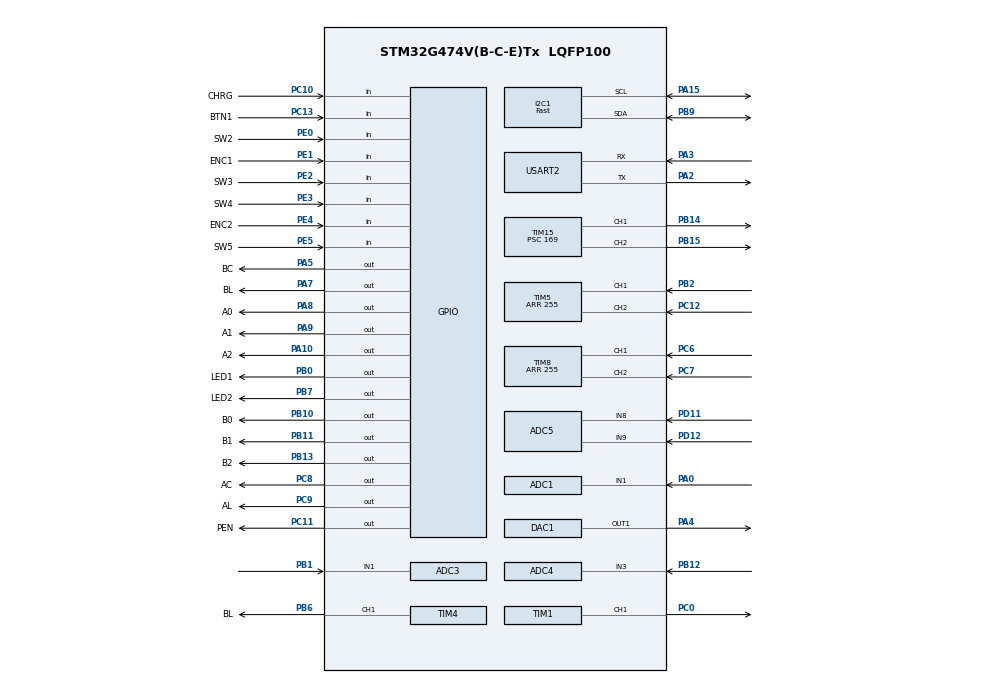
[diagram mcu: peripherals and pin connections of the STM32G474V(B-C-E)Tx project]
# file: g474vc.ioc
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ADC1.Channel-0\#ChannelRegularConversion=ADC_CHANNEL_1
ADC1.ClockPrescaler=ADC_CLOCK_ASYNC_DIV4
ADC1.ContinuousConvMode=ENABLE
ADC1.DMAAccessModeView=ENABLE
ADC1.DMAContinuousRequests=ENABLE
ADC1.Mode=ADC_DUALMODE_INTERL
ADC1.NbrOfConversionFlag=1
ADC1.OffsetNumber-0\#ChannelRegularConversion=ADC_OFFSET_NONE
ADC1.Rank-0\#ChannelRegularConversion=1
ADC1.Resolution=ADC_RESOLUTION_8B
ADC1.SamplingTime-0\#ChannelRegularConversion=ADC_SAMPLETIME_2CYCLES_5
ADC1.TwoSamplingDelay=ADC_TWOSAMPLINGDELAY_2CYCLES
ADC1.master=1
ADC2.Channel-0\#ChannelRegularConversion=ADC_CHANNEL_1
ADC2.ClockPrescaler=ADC_CLOCK_ASYNC_DIV4
ADC2.ContinuousConvMode=ENABLE
ADC2.DMAAccessModeView=ENABLE
ADC2.DMAContinuousRequests=DISABLE
ADC2.EOCSelection=ADC_EOC_SINGLE_CONV
ADC2.Mode=ADC_DUALMODE_INTERL
ADC2.NbrOfConversionFlag=1
ADC2.OffsetNumber-0\#ChannelRegularConversion=ADC_OFFSET_NONE
ADC2.Overrun=ADC_OVR_DATA_PRESERVED
ADC2.Rank-0\#ChannelRegularConversion=1
ADC2.Resolution=ADC_RESOLUTION_8B
ADC2.SamplingTime-0\#ChannelRegularConversion=ADC_SAMPLETIME_2CYCLES_5
ADC2.TwoSamplingDelay=ADC_TWOSAMPLINGDELAY_2CYCLES
ADC3.Channel-0\#ChannelRegularConversion=ADC_CHANNEL_1
ADC3.ClockPrescaler=ADC_CLOCK_ASYNC_DIV4
ADC3.ContinuousConvMode=ENABLE
ADC3.DMAAccessModeView=ENABLE
ADC3.DMAContinuousRequests=ENABLE
ADC3.Mode=ADC_DUALMODE_INTERL
ADC3.NbrOfConversionFlag=1
ADC3.OffsetNumber-0\#ChannelRegularConversion=ADC_OFFSET_NONE
ADC3.Rank-0\#ChannelRegularConversion=1
ADC3.Resolution=ADC_RESOLUTION_8B
ADC3.SamplingTime-0\#ChannelRegularConversion=ADC_SAMPLETIME_2CYCLES_5
ADC3.TwoSamplingDelay=ADC_TWOSAMPLINGDELAY_2CYCLES
ADC3.master=1
ADC4.Channel-0\#ChannelRegularConversion=ADC_CHANNEL_3
ADC4.ClockPrescaler=ADC_CLOCK_ASYNC_DIV4
ADC4.DMAAccessModeView=ENABLE
ADC4.Mode=ADC_DUALMODE_INTERL
ADC4.NbrOfConversionFlag=1
ADC4.OffsetNumber-0\#ChannelRegularConversion=ADC_OFFSET_NONE
ADC4.Rank-0\#ChannelRegularConversion=1
ADC4.Resolution=ADC_RESOLUTION_8B
ADC4.SamplingTime-0\#ChannelRegularConversion=ADC_SAMPLETIME_2CYCLES_5
ADC4.TwoSamplingDelay=ADC_TWOSAMPLINGDELAY_2CYCLES
ADC5.Channel-0\#ChannelRegularConversion=ADC_CHANNEL_8
ADC5.ClockPrescaler=ADC_CLOCK_ASYNC_DIV4
ADC5.NbrOfConversionFlag=1
ADC5.OffsetNumber-0\#ChannelRegularConversion=ADC_OFFSET_NONE
ADC5.Rank-0\#ChannelRegularConversion=1
ADC5.SamplingTime-0\#ChannelRegularConversion=ADC_SAMPLETIME_2CYCLES_5
DAC1.DAC_OutputBuffer-DAC_OUT1=DAC_OUTPUTBUFFER_DISABLE
DAC1.DAC_Trigger_OUT1-DAC_OUT1=DAC_TRIGGER_T4_TRGO
Dma.ADC1.1.Direction=DMA_PERIPH_TO_MEMORY
Dma.ADC1.1.EventEnable=DISABLE
Dma.ADC1.1.Instance=DMA2_Channel1
Dma.ADC1.1.MemDataAlignment=DMA_MDATAALIGN_HALFWORD
Dma.ADC1.1.MemInc=DMA_MINC_ENABLE
Dma.ADC1.1.Mode=DMA_NORMAL
Dma.ADC1.1.PeriphDataAlignment=DMA_PDATAALIGN_HALFWORD
Dma.ADC1.1.PeriphInc=DMA_PINC_DISABLE
Dma.ADC1.1.Polarity=HAL_DMAMUX_REQ_GEN_RISING
Dma.ADC1.1.Priority=DMA_PRIORITY_VERY_HIGH
Dma.ADC1.1.RequestNumber=1
Dma.ADC1.1.SignalID=NONE
Dma.ADC1.1.SyncEnable=DISABLE
Dma.ADC1.1.SyncPolarity=HAL_DMAMUX_SYNC_NO_EVENT
Dma.ADC1.1.SyncRequestNumber=1
Dma.ADC1.1.SyncSignalID=NONE
Dma.ADC3.2.Direction=DMA_PERIPH_TO_MEMORY
Dma.ADC3.2.EventEnable=DISABLE
Dma.ADC3.2.Instance=DMA1_Channel3
Dma.ADC3.2.MemDataAlignment=DMA_MDATAALIGN_HALFWORD
Dma.ADC3.2.MemInc=DMA_MINC_ENABLE
Dma.ADC3.2.Mode=DMA_NORMAL
Dma.ADC3.2.PeriphDataAlignment=DMA_PDATAALIGN_HALFWORD
Dma.ADC3.2.PeriphInc=DMA_PINC_DISABLE
Dma.ADC3.2.Polarity=HAL_DMAMUX_REQ_GEN_RISING
Dma.ADC3.2.Priority=DMA_PRIORITY_VERY_HIGH
Dma.ADC3.2.RequestNumber=1
Dma.ADC3.2.SignalID=NONE
Dma.ADC3.2.SyncEnable=DISABLE
Dma.ADC3.2.SyncPolarity=HAL_DMAMUX_SYNC_NO_EVENT
Dma.ADC3.2.SyncRequestNumber=1
Dma.ADC3.2.SyncSignalID=NONE
Dma.DAC1_CH1.0.Direction=DMA_MEMORY_TO_PERIPH
Dma.DAC1_CH1.0.EventEnable=DISABLE
Dma.DAC1_CH1.0.Instance=DMA1_Channel2
Dma.DAC1_CH1.0.MemDataAlignment=DMA_MDATAALIGN_HALFWORD
Dma.DAC1_CH1.0.MemInc=DMA_MINC_ENABLE
Dma.DAC1_CH1.0.Mode=DMA_CIRCULAR
Dma.DAC1_CH1.0.PeriphDataAlignment=DMA_PDATAALIGN_WORD
Dma.DAC1_CH1.0.PeriphInc=DMA_PINC_DISABLE
Dma.DAC1_CH1.0.Polarity=HAL_DMAMUX_REQ_GEN_RISING
Dma.DAC1_CH1.0.Priority=DMA_PRIORITY_HIGH
Dma.DAC1_CH1.0.RequestNumber=1
Dma.DAC1_CH1.0.SignalID=NONE
Dma.DAC1_CH1.0.SyncEnable=DISABLE
Dma.DAC1_CH1.0.SyncPolarity=HAL_DMAMUX_SYNC_NO_EVENT
Dma.DAC1_CH1.0.SyncRequestNumber=1
Dma.DAC1_CH1.0.SyncSignalID=NONE
Dma.Request0=DAC1_CH1
Dma.Request1=ADC1
Dma.Request2=ADC3
Dma.Request3=USART2_TX
Dma.USART2_TX.3.Direction=DMA_MEMORY_TO_PERIPH
Dma.USART2_TX.3.EventEnable=DISABLE
Dma.USART2_TX.3.Instance=DMA1_Channel1
Dma.USART2_TX.3.MemDataAlignment=DMA_MDATAALIGN_BYTE
Dma.USART2_TX.3.MemInc=DMA_MINC_ENABLE
Dma.USART2_TX.3.Mode=DMA_NORMAL
Dma.USART2_TX.3.PeriphDataAlignment=DMA_PDATAALIGN_BYTE
Dma.USART2_TX.3.PeriphInc=DMA_PINC_DISABLE
Dma.USART2_TX.3.Polarity=HAL_DMAMUX_REQ_GEN_RISING
Dma.USART2_TX.3.Priority=DMA_PRIORITY_LOW
Dma.USART2_TX.3.RequestNumber=1
Dma.USART2_TX.3.SignalID=NONE
Dma.USART2_TX.3.SyncEnable=DISABLE
Dma.USART2_TX.3.SyncPolarity=HAL_DMAMUX_SYNC_NO_EVENT
Dma.USART2_TX.3.SyncRequestNumber=1
Dma.USART2_TX.3.SyncSignalID=NONE
I2C1.I2C_Speed_Mode=I2C_Fast
I2C1.Timing=0x40621236
Mcu.Family=STM32G4
Mcu.Name=STM32G474V(B-C-E)Tx
Mcu.Package=LQFP100
NVIC.DMA1_Channel1_IRQn=true\:0\:0\:false\:false\:true\:false\:true\:true
NVIC.DMA1_Channel2_IRQn=true\:0\:0\:false\:false\:true\:false\:true\:true
NVIC.DMA1_Channel3_IRQn=true\:0\:0\:false\:false\:true\:false\:true\:true
NVIC.DMA2_Channel1_IRQn=true\:0\:0\:false\:false\:true\:false\:true\:true
NVIC.PriorityGroup=NVIC_PRIORITYGROUP_4
PA0.Signal=SharedAnalog_PA0
PA10.GPIO_Label=A2
PA10.Signal=GPIO_Output
PA11.Signal=USB_DM
PA12.Signal=USB_DP
PA13.Mode=Serial_Wire
PA13.Signal=SYS_JTMS-SWDIO
PA14.Mode=Serial_Wire
PA14.Signal=SYS_JTCK-SWCLK
PA15.Mode=I2C
PA15.Signal=I2C1_SCL
PA2.Mode=Asynchronous
PA2.Signal=USART2_TX
PA3.Mode=Asynchronous
PA3.Signal=USART2_RX
PA4.Signal=COMP_DAC11_group
PA5.GPIO_Label=BC
PA5.Signal=GPIO_Output
PA7.GPIO_Label=BL
PA7.Signal=GPIO_Output
PA8.GPIO_Label=A0
PA8.Signal=GPIO_Output
PA9.GPIO_Label=A1
PA9.Signal=GPIO_Output
PB0.GPIO_Label=LED1
PB0.Signal=GPIO_Output
PB1.Mode=IN1-Single-Ended
PB1.Signal=ADC3_IN1
PB10.GPIO_Label=B0
PB10.Signal=GPIO_Output
PB11.GPIO_Label=B1
PB11.Signal=GPIO_Output
PB12.Mode=IN3-Single-Ended
PB12.Signal=ADC4_IN3
PB13.GPIO_Label=B2
PB13.Signal=GPIO_Output
PB14.Signal=S_TIM15_CH1
PB15.Signal=S_TIM15_CH2
PB2.GPIO_PuPd=GPIO_PULLUP
PB2.Signal=S_TIM5_CH1
PB6.GPIO_Label=BL
PB6.GPIO_Speed=GPIO_SPEED_FREQ_HIGH
PB6.Signal=S_TIM4_CH1
PB7.GPIO_Label=LED2
PB7.Signal=GPIO_Output
PB9.Mode=I2C
PB9.Signal=I2C1_SDA
PC0.Signal=S_TIM1_CH1
PC1.Signal=QUADSPI1_BK2_IO0
PC10.GPIO_Label=CHRG
PC10.Signal=GPIO_Input
PC11.GPIO_Label=PEN
PC11.Signal=GPIO_Output
PC12.GPIO_PuPd=GPIO_PULLUP
PC12.Signal=S_TIM5_CH2
PC13.GPIO_Label=BTN1
PC13.GPIO_PuPd=GPIO_PULLUP
PC13.Signal=GPIO_Input
PC2.Signal=QUADSPI1_BK2_IO1
PC3.Signal=QUADSPI1_BK2_IO2
PC4.Signal=QUADSPI1_BK2_IO3
PC6.GPIO_PuPd=GPIO_PULLUP
PC6.Signal=S_TIM8_CH1
PC7.GPIO_PuPd=GPIO_PULLUP
PC7.Signal=S_TIM8_CH2
PC8.GPIO_Label=AC
PC8.Signal=GPIO_Output
PC9.GPIO_Label=AL
PC9.Signal=GPIO_Output
PD0.Signal=FMC_D2
PD1.Signal=FMC_D3
PD10.Signal=FMC_D15
PD11.Mode=IN8-Single-Ended
PD11.Signal=ADC5_IN8
PD12.Mode=IN9-Single-Ended
PD12.Signal=ADC5_IN9
PD13.Signal=FMC_A18
PD14.Signal=FMC_D0
PD15.Signal=FMC_D1
PD3.Signal=QUADSPI1_BK2_NCS
PD4.Signal=FMC_NOE
PD5.Signal=FMC_NWE
PD7.Signal=FMC_NE1
PD8.Signal=FMC_D13
PD9.Signal=FMC_D14
PE0.GPIO_Label=SW2
PE0.GPIO_PuPd=GPIO_PULLUP
PE0.Signal=GPIO_Input
PE1.GPIO_Label=ENC1
PE1.GPIO_PuPd=GPIO_PULLUP
PE1.Signal=GPIO_Input
PE10.Signal=FMC_D7
PE11.Signal=FMC_D8
PE12.Signal=FMC_D9
PE13.Signal=FMC_D10
PE14.Signal=FMC_D11
PE15.Signal=FMC_D12
PE2.GPIO_Label=SW3
PE2.GPIO_PuPd=GPIO_PULLUP
PE2.Signal=GPIO_Input
PE3.GPIO_Label=SW4
PE3.GPIO_PuPd=GPIO_PULLUP
PE3.Signal=GPIO_Input
PE4.GPIO_Label=ENC2
PE4.GPIO_PuPd=GPIO_PULLUP
PE4.Signal=GPIO_Input
PE5.GPIO_Label=SW5
PE5.GPIO_PuPd=GPIO_PULLUP
PE5.Signal=GPIO_Input
PE7.Signal=FMC_D4
PE8.Signal=FMC_D5
PE9.Signal=FMC_D6
PF0-OSC_IN.Mode=HSE-External-Oscillator
PF0-OSC_IN.Signal=RCC_OSC_IN
PF1-OSC_OUT.Mode=HSE-External-Oscillator
PF1-OSC_OUT.Signal=RCC_OSC_OUT
PF10.Signal=QUADSPI1_CLK
ProjectManager.HeapSize=0x200
ProjectManager.StackSize=0x400
ProjectManager.TargetToolchain=STM32CubeIDE
RCC.ADC12CLockSelection=RCC_ADC12CLKSOURCE_PLL
RCC.ADC12Freq_Value=113333333.33333333
RCC.ADC345CLockSelection=RCC_ADC345CLKSOURCE_PLL
RCC.ADC345Freq_Value=113333333.33333333
RCC.AHBFreq_Value=170000000
RCC.APB1Freq_Value=170000000
RCC.APB1TimFreq_Value=170000000
RCC.APB2Freq_Value=170000000
RCC.APB2TimFreq_Value=170000000
RCC.CK48CLockSelection=RCC_USBCLKSOURCE_HSI48
RCC.CortexFreq_Value=170000000
RCC.DATA_CACHE_ENABLE=0
RCC.EXTERNAL_CLOCK_VALUE=12288000
RCC.EnbaleCSS=true
RCC.HCLKFreq_Value=170000000
RCC.HSE_VALUE=8000000
RCC.HSI48_VALUE=48000000
RCC.HSI_VALUE=16000000
RCC.INSTRUCTION_CACHE_ENABLE=0
RCC.LSE_VALUE=32768
RCC.PLLM=RCC_PLLM_DIV2
RCC.PLLN=85
RCC.PLLP=RCC_PLLP_DIV3
RCC.PLLSourceVirtual=RCC_PLLSOURCE_HSE
RCC.SYSCLKFreq_VALUE=170000000
RCC.SYSCLKSource=RCC_SYSCLKSOURCE_PLLCLK
RCC.USBFreq_Value=48000000
RCC.VCOOutputFreq_Value=340000000
SH.COMP_DAC11_group.0=DAC1_OUT1,DAC_OUT1
SH.S_TIM15_CH1.0=TIM15_CH1,PWM Generation1 CH1
SH.S_TIM15_CH2.0=TIM15_CH2,PWM Generation2 CH2
SH.S_TIM1_CH1.0=TIM1_CH1,PWM Generation1 CH1
SH.S_TIM4_CH1.0=TIM4_CH1,PWM Generation1 CH1
SH.S_TIM5_CH1.0=TIM5_CH1,Encoder_Interface
SH.S_TIM5_CH2.0=TIM5_CH2,Encoder_Interface
SH.S_TIM8_CH1.0=TIM8_CH1,Encoder_Interface
SH.S_TIM8_CH2.0=TIM8_CH2,Encoder_Interface
SH.SharedAnalog_PA0.0=ADC1_IN1,IN1-Single-Ended
SH.SharedAnalog_PA0.1=ADC2_IN1,IN1-Single-Ended
TIM1.Channel-PWM\ Generation1\ CH1=TIM_CHANNEL_1
TIM1.PeriodNoDither=99
TIM1.Prescaler=99
TIM1.PulseNoDither_1=40
TIM15.Channel-PWM\ Generation1\ CH1=TIM_CHANNEL_1
TIM15.Channel-PWM\ Generation2\ CH2=TIM_CHANNEL_2
TIM15.PeriodNoDither=99
TIM15.Prescaler=169
TIM15.PulseNoDither_1=40
TIM15.PulseNoDither_2=70
TIM4.AutoReloadPreload=TIM_AUTORELOAD_PRELOAD_DISABLE
TIM4.Channel-PWM\ Generation1\ CH1=TIM_CHANNEL_1
TIM4.PeriodNoDither=5
TIM4.Prescaler=10
TIM4.PulseNoDither_1=3
TIM4.TIM_MasterOutputTrigger=TIM_TRGO_UPDATE
TIM5.EncoderMode=TIM_ENCODERMODE_TI12
TIM5.IC1Filter=6
TIM5.IC2Filter=6
TIM5.PeriodNoDither=255
TIM8.EncoderMode=TIM_ENCODERMODE_TI12
TIM8.IC1Filter=6
TIM8.IC2Filter=6
TIM8.PeriodNoDither=255
USART2.VirtualMode-Asynchronous=VM_ASYNC
VP_SYS_VS_DBSignals.Mode=DisableDeadBatterySignals
VP_TIM15_VS_ClockSourceINT.Mode=Internal
VP_TIM1_VS_ClockSourceINT.Mode=Internal
VP_TIM4_VS_ClockSourceINT.Mode=Internal
board=custom

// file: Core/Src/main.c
/* USER CODE BEGIN Header */
/**
  ******************************************************************************
  * @file           : main.c
  * @brief          : Main program body
  ******************************************************************************
  * @attention
  *
  * Copyright (c) 2026 STMicroelectronics.
  * All rights reserved.
  *
  * This software is licensed under terms that can be found in the LICENSE file
  * in the root directory of this software component.
  * If no LICENSE file comes with this software, it is provided AS-IS.
  *
  ******************************************************************************
  */
/* USER CODE END Header */
#include "main.h"

/* USER CODE BEGIN Includes */
#include <stdlib.h>

#include "_main.h"

/* USER CODE END Includes */

void SystemClock_Config(void);
static void MX_GPIO_Init(void);
static void MX_DMA_Init(void);
static void MX_TIM1_Init(void);
static void MX_TIM8_Init(void);
static void MX_TIM4_Init(void);
static void MX_DAC1_Init(void);
static void MX_ADC2_Init(void);
static void MX_ADC1_Init(void);
static void MX_ADC3_Init(void);
static void MX_ADC4_Init(void);
static void MX_I2C1_Init(void);
static void MX_TIM15_Init(void);
static void MX_TIM5_Init(void);
static void MX_ADC5_Init(void);
static void MX_USART2_UART_Init(void);

int main(void)
{

  /* MCU Configuration--------------------------------------------------------*/

  /* Reset of all peripherals, Initializes the Flash interface and the Systick. */
  LL_APB2_GRP1_EnableClock(LL_APB2_GRP1_PERIPH_SYSCFG);
  LL_APB1_GRP1_EnableClock(LL_APB1_GRP1_PERIPH_PWR);

  /* System interrupt init*/
  NVIC_SetPriorityGrouping(NVIC_PRIORITYGROUP_4);

  /* SysTick_IRQn interrupt configuration */
  NVIC_SetPriority(SysTick_IRQn, NVIC_EncodePriority(NVIC_GetPriorityGrouping(),15, 0));

  /** Disable the internal Pull-Up in Dead Battery pins of UCPD peripheral
  */
  LL_PWR_DisableUCPDDeadBattery();

  /* Configure the system clock */
  SystemClock_Config();

  /* Initialize all configured peripherals */
  MX_GPIO_Init();
  MX_DMA_Init();
  MX_TIM1_Init();
  MX_TIM8_Init();
  MX_TIM4_Init();
  MX_DAC1_Init();
  MX_ADC2_Init();
  MX_ADC1_Init();
  MX_ADC3_Init();
  MX_ADC4_Init();
  MX_I2C1_Init();
  MX_TIM15_Init();
  MX_TIM5_Init();
  MX_ADC5_Init();
  MX_USART2_UART_Init();

  /* Infinite loop */
  /* USER CODE BEGIN WHILE */
  mainInitialize();

  // ReSharper disable once CppDFAEndlessLoop
  while (1) {
    mainCycle();
    /* USER CODE END WHILE */

  }
}

void SystemClock_Config(void)
{
  LL_FLASH_SetLatency(LL_FLASH_LATENCY_4);
  while(LL_FLASH_GetLatency() != LL_FLASH_LATENCY_4)
  {
  }
  LL_PWR_EnableRange1BoostMode();
  LL_RCC_HSE_Enable();
   /* Wait till HSE is ready */
  while(LL_RCC_HSE_IsReady() != 1)
  {
  }

  LL_RCC_HSE_EnableCSS();
  LL_RCC_PLL_ConfigDomain_SYS(LL_RCC_PLLSOURCE_HSE, LL_RCC_PLLM_DIV_2, 85, LL_RCC_PLLR_DIV_2);
  LL_RCC_PLL_ConfigDomain_ADC(LL_RCC_PLLSOURCE_HSE, LL_RCC_PLLM_DIV_2, 85, LL_RCC_PLLP_DIV_3);
  LL_RCC_PLL_EnableDomain_SYS();
  LL_RCC_PLL_EnableDomain_ADC();
  LL_RCC_PLL_Enable();
   /* Wait till PLL is ready */
  while(LL_RCC_PLL_IsReady() != 1)
  {
  }

  LL_RCC_SetSysClkSource(LL_RCC_SYS_CLKSOURCE_PLL);
  LL_RCC_SetAHBPrescaler(LL_RCC_SYSCLK_DIV_2);
   /* Wait till System clock is ready */
  while(LL_RCC_GetSysClkSource() != LL_RCC_SYS_CLKSOURCE_STATUS_PLL)
  {
  }

  /* Insure 1us transition state at intermediate medium speed clock*/
  for (__IO uint32_t i = (170 >> 1); i !=0; i--);

  /* Set AHB prescaler*/
  LL_RCC_SetAHBPrescaler(LL_RCC_SYSCLK_DIV_1);
  LL_RCC_SetAPB1Prescaler(LL_RCC_APB1_DIV_1);
  LL_RCC_SetAPB2Prescaler(LL_RCC_APB2_DIV_1);

  LL_Init1msTick(170000000);

  LL_SetSystemCoreClock(170000000);
}

static void MX_ADC1_Init(void)
{

  LL_ADC_InitTypeDef ADC_InitStruct = {0};
  LL_ADC_REG_InitTypeDef ADC_REG_InitStruct = {0};
  LL_ADC_CommonInitTypeDef ADC_CommonInitStruct = {0};

  LL_GPIO_InitTypeDef GPIO_InitStruct = {0};

  LL_RCC_SetADCClockSource(LL_RCC_ADC12_CLKSOURCE_PLL);

  /* Peripheral clock enable */
  LL_AHB2_GRP1_EnableClock(LL_AHB2_GRP1_PERIPH_ADC12);

  LL_AHB2_GRP1_EnableClock(LL_AHB2_GRP1_PERIPH_GPIOA);
  /**ADC1 GPIO Configuration
  PA0   ------> ADC1_IN1
  */
  GPIO_InitStruct.Pin = LL_GPIO_PIN_0;
  GPIO_InitStruct.Mode = LL_GPIO_MODE_ANALOG;
  GPIO_InitStruct.Pull = LL_GPIO_PULL_NO;
  LL_GPIO_Init(GPIOA, &GPIO_InitStruct);

  /* ADC1 DMA Init */

  /* ADC1 Init */
  LL_DMA_SetPeriphRequest(DMA2, LL_DMA_CHANNEL_1, LL_DMAMUX_REQ_ADC1);

  LL_DMA_SetDataTransferDirection(DMA2, LL_DMA_CHANNEL_1, LL_DMA_DIRECTION_PERIPH_TO_MEMORY);

  LL_DMA_SetChannelPriorityLevel(DMA2, LL_DMA_CHANNEL_1, LL_DMA_PRIORITY_VERYHIGH);

  LL_DMA_SetMode(DMA2, LL_DMA_CHANNEL_1, LL_DMA_MODE_NORMAL);

  LL_DMA_SetPeriphIncMode(DMA2, LL_DMA_CHANNEL_1, LL_DMA_PERIPH_NOINCREMENT);

  LL_DMA_SetMemoryIncMode(DMA2, LL_DMA_CHANNEL_1, LL_DMA_MEMORY_INCREMENT);

  LL_DMA_SetPeriphSize(DMA2, LL_DMA_CHANNEL_1, LL_DMA_PDATAALIGN_HALFWORD);

  LL_DMA_SetMemorySize(DMA2, LL_DMA_CHANNEL_1, LL_DMA_MDATAALIGN_HALFWORD);

  /** Common config
  */
  ADC_InitStruct.Resolution = LL_ADC_RESOLUTION_8B;
  ADC_InitStruct.DataAlignment = LL_ADC_DATA_ALIGN_RIGHT;
  ADC_InitStruct.LowPowerMode = LL_ADC_LP_MODE_NONE;
  LL_ADC_Init(ADC1, &ADC_InitStruct);
  ADC_REG_InitStruct.TriggerSource = LL_ADC_REG_TRIG_SOFTWARE;
  ADC_REG_InitStruct.SequencerLength = LL_ADC_REG_SEQ_SCAN_DISABLE;
  ADC_REG_InitStruct.SequencerDiscont = LL_ADC_REG_SEQ_DISCONT_DISABLE;
  ADC_REG_InitStruct.ContinuousMode = LL_ADC_REG_CONV_CONTINUOUS;
  ADC_REG_InitStruct.DMATransfer = LL_ADC_REG_DMA_TRANSFER_UNLIMITED;
  ADC_REG_InitStruct.Overrun = LL_ADC_REG_OVR_DATA_PRESERVED;
  LL_ADC_REG_Init(ADC1, &ADC_REG_InitStruct);
  LL_ADC_SetGainCompensation(ADC1, 0);
  LL_ADC_SetOverSamplingScope(ADC1, LL_ADC_OVS_DISABLE);
  ADC_CommonInitStruct.CommonClock = LL_ADC_CLOCK_ASYNC_DIV4;
  ADC_CommonInitStruct.Multimode = LL_ADC_MULTI_DUAL_REG_INTERL;
  ADC_CommonInitStruct.MultiDMATransfer = LL_ADC_MULTI_REG_DMA_UNLMT_RES8_6B;
  ADC_CommonInitStruct.MultiTwoSamplingDelay = LL_ADC_MULTI_TWOSMP_DELAY_2CYCLES;
  LL_ADC_CommonInit(__LL_ADC_COMMON_INSTANCE(ADC1), &ADC_CommonInitStruct);

  /* Disable ADC deep power down (enabled by default after reset state) */
  LL_ADC_DisableDeepPowerDown(ADC1);
  /* Enable ADC internal voltage regulator */
  LL_ADC_EnableInternalRegulator(ADC1);
  /* Delay for ADC internal voltage regulator stabilization. */
  /* Compute number of CPU cycles to wait for, from delay in us. */
  /* Note: Variable divided by 2 to compensate partially */
  /* CPU processing cycles (depends on compilation optimization). */
  /* Note: If system core clock frequency is below 200kHz, wait time */
  /* is only a few CPU processing cycles. */
  uint32_t wait_loop_index;
  wait_loop_index = ((LL_ADC_DELAY_INTERNAL_REGUL_STAB_US * (SystemCoreClock / (100000 * 2))) / 10);
  while(wait_loop_index != 0)
  {
    wait_loop_index--;
  }

  /** Configure Regular Channel
  */
  LL_ADC_REG_SetSequencerRanks(ADC1, LL_ADC_REG_RANK_1, LL_ADC_CHANNEL_1);
  LL_ADC_SetChannelSamplingTime(ADC1, LL_ADC_CHANNEL_1, LL_ADC_SAMPLINGTIME_2CYCLES_5);
  LL_ADC_SetChannelSingleDiff(ADC1, LL_ADC_CHANNEL_1, LL_ADC_SINGLE_ENDED);
  /* USER CODE BEGIN ADC1_Init 2 */
  LL_ADC_StartCalibration(ADC1, LL_ADC_SINGLE_ENDED);
  while (LL_ADC_IsCalibrationOnGoing(ADC1) != 0) {}
  /* USER CODE END ADC1_Init 2 */

}

static void MX_ADC2_Init(void)
{

  LL_ADC_InitTypeDef ADC_InitStruct = {0};
  LL_ADC_REG_InitTypeDef ADC_REG_InitStruct = {0};

  LL_GPIO_InitTypeDef GPIO_InitStruct = {0};

  LL_RCC_SetADCClockSource(LL_RCC_ADC12_CLKSOURCE_PLL);

  /* Peripheral clock enable */
  LL_AHB2_GRP1_EnableClock(LL_AHB2_GRP1_PERIPH_ADC12);

  LL_AHB2_GRP1_EnableClock(LL_AHB2_GRP1_PERIPH_GPIOA);
  /**ADC2 GPIO Configuration
  PA0   ------> ADC2_IN1
  */
  GPIO_InitStruct.Pin = LL_GPIO_PIN_0;
  GPIO_InitStruct.Mode = LL_GPIO_MODE_ANALOG;
  GPIO_InitStruct.Pull = LL_GPIO_PULL_NO;
  LL_GPIO_Init(GPIOA, &GPIO_InitStruct);

  /** Common config
  */
  ADC_InitStruct.Resolution = LL_ADC_RESOLUTION_8B;
  ADC_InitStruct.DataAlignment = LL_ADC_DATA_ALIGN_RIGHT;
  ADC_InitStruct.LowPowerMode = LL_ADC_LP_MODE_NONE;
  LL_ADC_Init(ADC2, &ADC_InitStruct);
  ADC_REG_InitStruct.SequencerLength = LL_ADC_REG_SEQ_SCAN_DISABLE;
  ADC_REG_InitStruct.SequencerDiscont = LL_ADC_REG_SEQ_DISCONT_DISABLE;
  ADC_REG_InitStruct.ContinuousMode = LL_ADC_REG_CONV_CONTINUOUS;
  ADC_REG_InitStruct.DMATransfer = LL_ADC_REG_DMA_TRANSFER_NONE;
  ADC_REG_InitStruct.Overrun = LL_ADC_REG_OVR_DATA_PRESERVED;
  LL_ADC_REG_Init(ADC2, &ADC_REG_InitStruct);
  LL_ADC_SetGainCompensation(ADC2, 0);
  LL_ADC_SetOverSamplingScope(ADC2, LL_ADC_OVS_DISABLE);

  /* Disable ADC deep power down (enabled by default after reset state) */
  LL_ADC_DisableDeepPowerDown(ADC2);
  /* Enable ADC internal voltage regulator */
  LL_ADC_EnableInternalRegulator(ADC2);
  /* Delay for ADC internal voltage regulator stabilization. */
  /* Compute number of CPU cycles to wait for, from delay in us. */
  /* Note: Variable divided by 2 to compensate partially */
  /* CPU processing cycles (depends on compilation optimization). */
  /* Note: If system core clock frequency is below 200kHz, wait time */
  /* is only a few CPU processing cycles. */
  uint32_t wait_loop_index;
  wait_loop_index = ((LL_ADC_DELAY_INTERNAL_REGUL_STAB_US * (SystemCoreClock / (100000 * 2))) / 10);
  while(wait_loop_index != 0)
  {
    wait_loop_index--;
  }

  /** Configure Regular Channel
  */
  LL_ADC_REG_SetSequencerRanks(ADC2, LL_ADC_REG_RANK_1, LL_ADC_CHANNEL_1);
  LL_ADC_SetChannelSamplingTime(ADC2, LL_ADC_CHANNEL_1, LL_ADC_SAMPLINGTIME_2CYCLES_5);
  LL_ADC_SetChannelSingleDiff(ADC2, LL_ADC_CHANNEL_1, LL_ADC_SINGLE_ENDED);
  /* USER CODE BEGIN ADC2_Init 2 */
  /* Run ADC self calibration */
  LL_ADC_StartCalibration(ADC2, LL_ADC_SINGLE_ENDED);
  while (LL_ADC_IsCalibrationOnGoing(ADC2) != 0) {}
  // DWT_Delay_us(100);
  /* USER CODE END ADC2_Init 2 */

}

static void MX_ADC3_Init(void)
{

  LL_ADC_InitTypeDef ADC_InitStruct = {0};
  LL_ADC_REG_InitTypeDef ADC_REG_InitStruct = {0};
  LL_ADC_CommonInitTypeDef ADC_CommonInitStruct = {0};

  LL_GPIO_InitTypeDef GPIO_InitStruct = {0};

  LL_RCC_SetADCClockSource(LL_RCC_ADC345_CLKSOURCE_PLL);

  /* Peripheral clock enable */
  LL_AHB2_GRP1_EnableClock(LL_AHB2_GRP1_PERIPH_ADC345);

  LL_AHB2_GRP1_EnableClock(LL_AHB2_GRP1_PERIPH_GPIOB);
  /**ADC3 GPIO Configuration
  PB1   ------> ADC3_IN1
  */
  GPIO_InitStruct.Pin = LL_GPIO_PIN_1;
  GPIO_InitStruct.Mode = LL_GPIO_MODE_ANALOG;
  GPIO_InitStruct.Pull = LL_GPIO_PULL_NO;
  LL_GPIO_Init(GPIOB, &GPIO_InitStruct);

  /* ADC3 DMA Init */

  /* ADC3 Init */
  LL_DMA_SetPeriphRequest(DMA1, LL_DMA_CHANNEL_3, LL_DMAMUX_REQ_ADC3);

  LL_DMA_SetDataTransferDirection(DMA1, LL_DMA_CHANNEL_3, LL_DMA_DIRECTION_PERIPH_TO_MEMORY);

  LL_DMA_SetChannelPriorityLevel(DMA1, LL_DMA_CHANNEL_3, LL_DMA_PRIORITY_VERYHIGH);

  LL_DMA_SetMode(DMA1, LL_DMA_CHANNEL_3, LL_DMA_MODE_NORMAL);

  LL_DMA_SetPeriphIncMode(DMA1, LL_DMA_CHANNEL_3, LL_DMA_PERIPH_NOINCREMENT);

  LL_DMA_SetMemoryIncMode(DMA1, LL_DMA_CHANNEL_3, LL_DMA_MEMORY_INCREMENT);

  LL_DMA_SetPeriphSize(DMA1, LL_DMA_CHANNEL_3, LL_DMA_PDATAALIGN_HALFWORD);

  LL_DMA_SetMemorySize(DMA1, LL_DMA_CHANNEL_3, LL_DMA_MDATAALIGN_HALFWORD);

  /** Common config
  */
  ADC_InitStruct.Resolution = LL_ADC_RESOLUTION_8B;
  ADC_InitStruct.DataAlignment = LL_ADC_DATA_ALIGN_RIGHT;
  ADC_InitStruct.LowPowerMode = LL_ADC_LP_MODE_NONE;
  LL_ADC_Init(ADC3, &ADC_InitStruct);
  ADC_REG_InitStruct.TriggerSource = LL_ADC_REG_TRIG_SOFTWARE;
  ADC_REG_InitStruct.SequencerLength = LL_ADC_REG_SEQ_SCAN_DISABLE;
  ADC_REG_InitStruct.SequencerDiscont = LL_ADC_REG_SEQ_DISCONT_DISABLE;
  ADC_REG_InitStruct.ContinuousMode = LL_ADC_REG_CONV_CONTINUOUS;
  ADC_REG_InitStruct.DMATransfer = LL_ADC_REG_DMA_TRANSFER_UNLIMITED;
  ADC_REG_InitStruct.Overrun = LL_ADC_REG_OVR_DATA_PRESERVED;
  LL_ADC_REG_Init(ADC3, &ADC_REG_InitStruct);
  LL_ADC_SetGainCompensation(ADC3, 0);
  LL_ADC_SetOverSamplingScope(ADC3, LL_ADC_OVS_DISABLE);
  ADC_CommonInitStruct.CommonClock = LL_ADC_CLOCK_ASYNC_DIV4;
  ADC_CommonInitStruct.Multimode = LL_ADC_MULTI_DUAL_REG_INTERL;
  ADC_CommonInitStruct.MultiDMATransfer = LL_ADC_MULTI_REG_DMA_UNLMT_RES8_6B;
  ADC_CommonInitStruct.MultiTwoSamplingDelay = LL_ADC_MULTI_TWOSMP_DELAY_2CYCLES;
  LL_ADC_CommonInit(__LL_ADC_COMMON_INSTANCE(ADC3), &ADC_CommonInitStruct);

  /* Disable ADC deep power down (enabled by default after reset state) */
  LL_ADC_DisableDeepPowerDown(ADC3);
  /* Enable ADC internal voltage regulator */
  LL_ADC_EnableInternalRegulator(ADC3);
  /* Delay for ADC internal voltage regulator stabilization. */
  /* Compute number of CPU cycles to wait for, from delay in us. */
  /* Note: Variable divided by 2 to compensate partially */
  /* CPU processing cycles (depends on compilation optimization). */
  /* Note: If system core clock frequency is below 200kHz, wait time */
  /* is only a few CPU processing cycles. */
  uint32_t wait_loop_index;
  wait_loop_index = ((LL_ADC_DELAY_INTERNAL_REGUL_STAB_US * (SystemCoreClock / (100000 * 2))) / 10);
  while(wait_loop_index != 0)
  {
    wait_loop_index--;
  }

  /** Configure Regular Channel
  */
  LL_ADC_REG_SetSequencerRanks(ADC3, LL_ADC_REG_RANK_1, LL_ADC_CHANNEL_1);
  LL_ADC_SetChannelSamplingTime(ADC3, LL_ADC_CHANNEL_1, LL_ADC_SAMPLINGTIME_2CYCLES_5);
  LL_ADC_SetChannelSingleDiff(ADC3, LL_ADC_CHANNEL_1, LL_ADC_SINGLE_ENDED);
  /* USER CODE BEGIN ADC3_Init 2 */
  LL_ADC_StartCalibration(ADC3, LL_ADC_SINGLE_ENDED);
  while (LL_ADC_IsCalibrationOnGoing(ADC3) != 0) {}
  /* USER CODE END ADC3_Init 2 */

}

static void MX_ADC4_Init(void)
{

  LL_ADC_InitTypeDef ADC_InitStruct = {0};
  LL_ADC_REG_InitTypeDef ADC_REG_InitStruct = {0};

  LL_GPIO_InitTypeDef GPIO_InitStruct = {0};

  LL_RCC_SetADCClockSource(LL_RCC_ADC345_CLKSOURCE_PLL);

  /* Peripheral clock enable */
  LL_AHB2_GRP1_EnableClock(LL_AHB2_GRP1_PERIPH_ADC345);

  LL_AHB2_GRP1_EnableClock(LL_AHB2_GRP1_PERIPH_GPIOB);
  /**ADC4 GPIO Configuration
  PB12   ------> ADC4_IN3
  */
  GPIO_InitStruct.Pin = LL_GPIO_PIN_12;
  GPIO_InitStruct.Mode = LL_GPIO_MODE_ANALOG;
  GPIO_InitStruct.Pull = LL_GPIO_PULL_NO;
  LL_GPIO_Init(GPIOB, &GPIO_InitStruct);

  /** Common config
  */
  ADC_InitStruct.Resolution = LL_ADC_RESOLUTION_8B;
  ADC_InitStruct.DataAlignment = LL_ADC_DATA_ALIGN_RIGHT;
  ADC_InitStruct.LowPowerMode = LL_ADC_LP_MODE_NONE;
  LL_ADC_Init(ADC4, &ADC_InitStruct);
  ADC_REG_InitStruct.SequencerLength = LL_ADC_REG_SEQ_SCAN_DISABLE;
  ADC_REG_InitStruct.SequencerDiscont = LL_ADC_REG_SEQ_DISCONT_DISABLE;
  ADC_REG_InitStruct.ContinuousMode = LL_ADC_REG_CONV_CONTINUOUS;
  ADC_REG_InitStruct.DMATransfer = LL_ADC_REG_DMA_TRANSFER_NONE;
  ADC_REG_InitStruct.Overrun = LL_ADC_REG_OVR_DATA_PRESERVED;
  LL_ADC_REG_Init(ADC4, &ADC_REG_InitStruct);
  LL_ADC_SetGainCompensation(ADC4, 0);
  LL_ADC_SetOverSamplingScope(ADC4, LL_ADC_OVS_DISABLE);

  /* Disable ADC deep power down (enabled by default after reset state) */
  LL_ADC_DisableDeepPowerDown(ADC4);
  /* Enable ADC internal voltage regulator */
  LL_ADC_EnableInternalRegulator(ADC4);
  /* Delay for ADC internal voltage regulator stabilization. */
  /* Compute number of CPU cycles to wait for, from delay in us. */
  /* Note: Variable divided by 2 to compensate partially */
  /* CPU processing cycles (depends on compilation optimization). */
  /* Note: If system core clock frequency is below 200kHz, wait time */
  /* is only a few CPU processing cycles. */
  uint32_t wait_loop_index;
  wait_loop_index = ((LL_ADC_DELAY_INTERNAL_REGUL_STAB_US * (SystemCoreClock / (100000 * 2))) / 10);
  while(wait_loop_index != 0)
  {
    wait_loop_index--;
  }

  /** Configure Regular Channel
  */
  LL_ADC_REG_SetSequencerRanks(ADC4, LL_ADC_REG_RANK_1, LL_ADC_CHANNEL_3);
  LL_ADC_SetChannelSamplingTime(ADC4, LL_ADC_CHANNEL_3, LL_ADC_SAMPLINGTIME_2CYCLES_5);
  LL_ADC_SetChannelSingleDiff(ADC4, LL_ADC_CHANNEL_3, LL_ADC_SINGLE_ENDED);
  /* USER CODE BEGIN ADC4_Init 2 */
  LL_ADC_StartCalibration(ADC4, LL_ADC_SINGLE_ENDED);
  while (LL_ADC_IsCalibrationOnGoing(ADC4) != 0) {}
  /* USER CODE END ADC4_Init 2 */

}

static void MX_ADC5_Init(void)
{

  LL_ADC_InitTypeDef ADC_InitStruct = {0};
  LL_ADC_REG_InitTypeDef ADC_REG_InitStruct = {0};

  LL_GPIO_InitTypeDef GPIO_InitStruct = {0};

  LL_RCC_SetADCClockSource(LL_RCC_ADC345_CLKSOURCE_PLL);

  /* Peripheral clock enable */
  LL_AHB2_GRP1_EnableClock(LL_AHB2_GRP1_PERIPH_ADC345);

  LL_AHB2_GRP1_EnableClock(LL_AHB2_GRP1_PERIPH_GPIOD);
  /**ADC5 GPIO Configuration
  PD11   ------> ADC5_IN8
  PD12   ------> ADC5_IN9
  */
  GPIO_InitStruct.Pin = LL_GPIO_PIN_11;
  GPIO_InitStruct.Mode = LL_GPIO_MODE_ANALOG;
  GPIO_InitStruct.Pull = LL_GPIO_PULL_NO;
  LL_GPIO_Init(GPIOD, &GPIO_InitStruct);

  GPIO_InitStruct.Pin = LL_GPIO_PIN_12;
  GPIO_InitStruct.Mode = LL_GPIO_MODE_ANALOG;
  GPIO_InitStruct.Pull = LL_GPIO_PULL_NO;
  LL_GPIO_Init(GPIOD, &GPIO_InitStruct);

  /** Common config
  */
  ADC_InitStruct.Resolution = LL_ADC_RESOLUTION_12B;
  ADC_InitStruct.DataAlignment = LL_ADC_DATA_ALIGN_RIGHT;
  ADC_InitStruct.LowPowerMode = LL_ADC_LP_MODE_NONE;
  LL_ADC_Init(ADC5, &ADC_InitStruct);
  ADC_REG_InitStruct.TriggerSource = LL_ADC_REG_TRIG_SOFTWARE;
  ADC_REG_InitStruct.SequencerLength = LL_ADC_REG_SEQ_SCAN_DISABLE;
  ADC_REG_InitStruct.SequencerDiscont = LL_ADC_REG_SEQ_DISCONT_DISABLE;
  ADC_REG_InitStruct.ContinuousMode = LL_ADC_REG_CONV_SINGLE;
  ADC_REG_InitStruct.DMATransfer = LL_ADC_REG_DMA_TRANSFER_NONE;
  ADC_REG_InitStruct.Overrun = LL_ADC_REG_OVR_DATA_PRESERVED;
  LL_ADC_REG_Init(ADC5, &ADC_REG_InitStruct);
  LL_ADC_SetGainCompensation(ADC5, 0);
  LL_ADC_SetOverSamplingScope(ADC5, LL_ADC_OVS_DISABLE);
  LL_ADC_SetCommonClock(__LL_ADC_COMMON_INSTANCE(ADC5), LL_ADC_CLOCK_ASYNC_DIV4);

  /* Disable ADC deep power down (enabled by default after reset state) */
  LL_ADC_DisableDeepPowerDown(ADC5);
  /* Enable ADC internal voltage regulator */
  LL_ADC_EnableInternalRegulator(ADC5);
  /* Delay for ADC internal voltage regulator stabilization. */
  /* Compute number of CPU cycles to wait for, from delay in us. */
  /* Note: Variable divided by 2 to compensate partially */
  /* CPU processing cycles (depends on compilation optimization). */
  /* Note: If system core clock frequency is below 200kHz, wait time */
  /* is only a few CPU processing cycles. */
  uint32_t wait_loop_index;
  wait_loop_index = ((LL_ADC_DELAY_INTERNAL_REGUL_STAB_US * (SystemCoreClock / (100000 * 2))) / 10);
  while(wait_loop_index != 0)
  {
    wait_loop_index--;
  }

  /** Configure Regular Channel
  */
  LL_ADC_REG_SetSequencerRanks(ADC5, LL_ADC_REG_RANK_1, LL_ADC_CHANNEL_8);
  LL_ADC_SetChannelSamplingTime(ADC5, LL_ADC_CHANNEL_8, LL_ADC_SAMPLINGTIME_2CYCLES_5);
  LL_ADC_SetChannelSingleDiff(ADC5, LL_ADC_CHANNEL_8, LL_ADC_SINGLE_ENDED);

}

static void MX_DAC1_Init(void)
{

  LL_DAC_InitTypeDef DAC_InitStruct = {0};

  LL_GPIO_InitTypeDef GPIO_InitStruct = {0};

  /* Peripheral clock enable */
  LL_AHB2_GRP1_EnableClock(LL_AHB2_GRP1_PERIPH_DAC1);

  LL_AHB2_GRP1_EnableClock(LL_AHB2_GRP1_PERIPH_GPIOA);
  /**DAC1 GPIO Configuration
  PA4   ------> DAC1_OUT1
  */
  GPIO_InitStruct.Pin = LL_GPIO_PIN_4;
  GPIO_InitStruct.Mode = LL_GPIO_MODE_ANALOG;
  GPIO_InitStruct.Pull = LL_GPIO_PULL_NO;
  LL_GPIO_Init(GPIOA, &GPIO_InitStruct);

  /* DAC1 DMA Init */

  /* DAC1_CH1 Init */
  LL_DMA_SetPeriphRequest(DMA1, LL_DMA_CHANNEL_2, LL_DMAMUX_REQ_DAC1_CH1);

  LL_DMA_SetDataTransferDirection(DMA1, LL_DMA_CHANNEL_2, LL_DMA_DIRECTION_MEMORY_TO_PERIPH);

  LL_DMA_SetChannelPriorityLevel(DMA1, LL_DMA_CHANNEL_2, LL_DMA_PRIORITY_HIGH);

  LL_DMA_SetMode(DMA1, LL_DMA_CHANNEL_2, LL_DMA_MODE_CIRCULAR);

  LL_DMA_SetPeriphIncMode(DMA1, LL_DMA_CHANNEL_2, LL_DMA_PERIPH_NOINCREMENT);

  LL_DMA_SetMemoryIncMode(DMA1, LL_DMA_CHANNEL_2, LL_DMA_MEMORY_INCREMENT);

  LL_DMA_SetPeriphSize(DMA1, LL_DMA_CHANNEL_2, LL_DMA_PDATAALIGN_WORD);

  LL_DMA_SetMemorySize(DMA1, LL_DMA_CHANNEL_2, LL_DMA_MDATAALIGN_HALFWORD);

  /** DAC channel OUT1 config
  */
  LL_DAC_SetSignedFormat(DAC1, LL_DAC_CHANNEL_1, LL_DAC_SIGNED_FORMAT_DISABLE);
  DAC_InitStruct.TriggerSource = LL_DAC_TRIG_EXT_TIM4_TRGO;
  DAC_InitStruct.TriggerSource2 = LL_DAC_TRIG_SOFTWARE;
  DAC_InitStruct.WaveAutoGeneration = LL_DAC_WAVE_AUTO_GENERATION_NONE;
  DAC_InitStruct.OutputBuffer = LL_DAC_OUTPUT_BUFFER_DISABLE;
  DAC_InitStruct.OutputConnection = LL_DAC_OUTPUT_CONNECT_GPIO;
  DAC_InitStruct.OutputMode = LL_DAC_OUTPUT_MODE_NORMAL;
  LL_DAC_Init(DAC1, LL_DAC_CHANNEL_1, &DAC_InitStruct);
  LL_DAC_EnableTrigger(DAC1, LL_DAC_CHANNEL_1);
  LL_DAC_DisableDMADoubleDataMode(DAC1, LL_DAC_CHANNEL_1);

}

static void MX_I2C1_Init(void)
{

  LL_I2C_InitTypeDef I2C_InitStruct = {0};

  LL_GPIO_InitTypeDef GPIO_InitStruct = {0};

  LL_RCC_SetI2CClockSource(LL_RCC_I2C1_CLKSOURCE_PCLK1);

  LL_AHB2_GRP1_EnableClock(LL_AHB2_GRP1_PERIPH_GPIOA);
  LL_AHB2_GRP1_EnableClock(LL_AHB2_GRP1_PERIPH_GPIOB);
  /**I2C1 GPIO Configuration
  PA15   ------> I2C1_SCL
  PB9   ------> I2C1_SDA
  */
  GPIO_InitStruct.Pin = LL_GPIO_PIN_15;
  GPIO_InitStruct.Mode = LL_GPIO_MODE_ALTERNATE;
  GPIO_InitStruct.Speed = LL_GPIO_SPEED_FREQ_LOW;
  GPIO_InitStruct.OutputType = LL_GPIO_OUTPUT_OPENDRAIN;
  GPIO_InitStruct.Pull = LL_GPIO_PULL_NO;
  GPIO_InitStruct.Alternate = LL_GPIO_AF_4;
  LL_GPIO_Init(GPIOA, &GPIO_InitStruct);

  GPIO_InitStruct.Pin = LL_GPIO_PIN_9;
  GPIO_InitStruct.Mode = LL_GPIO_MODE_ALTERNATE;
  GPIO_InitStruct.Speed = LL_GPIO_SPEED_FREQ_LOW;
  GPIO_InitStruct.OutputType = LL_GPIO_OUTPUT_OPENDRAIN;
  GPIO_InitStruct.Pull = LL_GPIO_PULL_NO;
  GPIO_InitStruct.Alternate = LL_GPIO_AF_4;
  LL_GPIO_Init(GPIOB, &GPIO_InitStruct);

  /* Peripheral clock enable */
  LL_APB1_GRP1_EnableClock(LL_APB1_GRP1_PERIPH_I2C1);

  /** I2C Initialization
  */
  I2C_InitStruct.PeripheralMode = LL_I2C_MODE_I2C;
  I2C_InitStruct.Timing = 0x40621236;
  I2C_InitStruct.AnalogFilter = LL_I2C_ANALOGFILTER_ENABLE;
  I2C_InitStruct.DigitalFilter = 0;
  I2C_InitStruct.OwnAddress1 = 0;
  I2C_InitStruct.TypeAcknowledge = LL_I2C_ACK;
  I2C_InitStruct.OwnAddrSize = LL_I2C_OWNADDRESS1_7BIT;
  LL_I2C_Init(I2C1, &I2C_InitStruct);
  LL_I2C_EnableAutoEndMode(I2C1);
  LL_I2C_SetOwnAddress2(I2C1, 0, LL_I2C_OWNADDRESS2_NOMASK);
  LL_I2C_DisableOwnAddress2(I2C1);
  LL_I2C_DisableGeneralCall(I2C1);
  LL_I2C_EnableClockStretching(I2C1);

}

static void MX_TIM1_Init(void)
{

  LL_TIM_InitTypeDef TIM_InitStruct = {0};
  LL_TIM_OC_InitTypeDef TIM_OC_InitStruct = {0};
  LL_TIM_BDTR_InitTypeDef TIM_BDTRInitStruct = {0};

  LL_GPIO_InitTypeDef GPIO_InitStruct = {0};

  /* Peripheral clock enable */
  LL_APB2_GRP1_EnableClock(LL_APB2_GRP1_PERIPH_TIM1);

  TIM_InitStruct.Prescaler = 99;
  TIM_InitStruct.CounterMode = LL_TIM_COUNTERMODE_UP;
  TIM_InitStruct.Autoreload = 99;
  TIM_InitStruct.ClockDivision = LL_TIM_CLOCKDIVISION_DIV1;
  TIM_InitStruct.RepetitionCounter = 0;
  LL_TIM_Init(TIM1, &TIM_InitStruct);
  LL_TIM_DisableARRPreload(TIM1);
  LL_TIM_SetClockSource(TIM1, LL_TIM_CLOCKSOURCE_INTERNAL);
  LL_TIM_OC_EnablePreload(TIM1, LL_TIM_CHANNEL_CH1);
  TIM_OC_InitStruct.OCMode = LL_TIM_OCMODE_PWM1;
  TIM_OC_InitStruct.OCState = LL_TIM_OCSTATE_DISABLE;
  TIM_OC_InitStruct.OCNState = LL_TIM_OCSTATE_DISABLE;
  TIM_OC_InitStruct.CompareValue = 40;
  TIM_OC_InitStruct.OCPolarity = LL_TIM_OCPOLARITY_HIGH;
  TIM_OC_InitStruct.OCNPolarity = LL_TIM_OCPOLARITY_HIGH;
  TIM_OC_InitStruct.OCIdleState = LL_TIM_OCIDLESTATE_LOW;
  TIM_OC_InitStruct.OCNIdleState = LL_TIM_OCIDLESTATE_LOW;
  LL_TIM_OC_Init(TIM1, LL_TIM_CHANNEL_CH1, &TIM_OC_InitStruct);
  LL_TIM_OC_DisableFast(TIM1, LL_TIM_CHANNEL_CH1);
  LL_TIM_SetTriggerOutput(TIM1, LL_TIM_TRGO_RESET);
  LL_TIM_SetTriggerOutput2(TIM1, LL_TIM_TRGO2_RESET);
  LL_TIM_DisableMasterSlaveMode(TIM1);
  TIM_BDTRInitStruct.OSSRState = LL_TIM_OSSR_DISABLE;
  TIM_BDTRInitStruct.OSSIState = LL_TIM_OSSI_DISABLE;
  TIM_BDTRInitStruct.LockLevel = LL_TIM_LOCKLEVEL_OFF;
  TIM_BDTRInitStruct.DeadTime = 0;
  TIM_BDTRInitStruct.BreakState = LL_TIM_BREAK_DISABLE;
  TIM_BDTRInitStruct.BreakPolarity = LL_TIM_BREAK_POLARITY_HIGH;
  TIM_BDTRInitStruct.BreakFilter = LL_TIM_BREAK_FILTER_FDIV1;
  TIM_BDTRInitStruct.BreakAFMode = LL_TIM_BREAK_AFMODE_INPUT;
  TIM_BDTRInitStruct.Break2State = LL_TIM_BREAK2_DISABLE;
  TIM_BDTRInitStruct.Break2Polarity = LL_TIM_BREAK2_POLARITY_HIGH;
  TIM_BDTRInitStruct.Break2Filter = LL_TIM_BREAK2_FILTER_FDIV1;
  TIM_BDTRInitStruct.Break2AFMode = LL_TIM_BREAK_AFMODE_INPUT;
  TIM_BDTRInitStruct.AutomaticOutput = LL_TIM_AUTOMATICOUTPUT_DISABLE;
  LL_TIM_BDTR_Init(TIM1, &TIM_BDTRInitStruct);
  LL_AHB2_GRP1_EnableClock(LL_AHB2_GRP1_PERIPH_GPIOC);
  /**TIM1 GPIO Configuration
  PC0   ------> TIM1_CH1
  */
  GPIO_InitStruct.Pin = LL_GPIO_PIN_0;
  GPIO_InitStruct.Mode = LL_GPIO_MODE_ALTERNATE;
  GPIO_InitStruct.Speed = LL_GPIO_SPEED_FREQ_LOW;
  GPIO_InitStruct.OutputType = LL_GPIO_OUTPUT_PUSHPULL;
  GPIO_InitStruct.Pull = LL_GPIO_PULL_NO;
  GPIO_InitStruct.Alternate = LL_GPIO_AF_2;
  LL_GPIO_Init(GPIOC, &GPIO_InitStruct);

}

static void MX_TIM4_Init(void)
{

  LL_TIM_InitTypeDef TIM_InitStruct = {0};
  LL_TIM_OC_InitTypeDef TIM_OC_InitStruct = {0};

  LL_GPIO_InitTypeDef GPIO_InitStruct = {0};

  /* Peripheral clock enable */
  LL_APB1_GRP1_EnableClock(LL_APB1_GRP1_PERIPH_TIM4);

  TIM_InitStruct.Prescaler = 10;
  TIM_InitStruct.CounterMode = LL_TIM_COUNTERMODE_UP;
  TIM_InitStruct.Autoreload = 5;
  TIM_InitStruct.ClockDivision = LL_TIM_CLOCKDIVISION_DIV1;
  LL_TIM_Init(TIM4, &TIM_InitStruct);
  LL_TIM_DisableARRPreload(TIM4);
  LL_TIM_SetClockSource(TIM4, LL_TIM_CLOCKSOURCE_INTERNAL);
  LL_TIM_OC_EnablePreload(TIM4, LL_TIM_CHANNEL_CH1);
  TIM_OC_InitStruct.OCMode = LL_TIM_OCMODE_PWM1;
  TIM_OC_InitStruct.OCState = LL_TIM_OCSTATE_DISABLE;
  TIM_OC_InitStruct.OCNState = LL_TIM_OCSTATE_DISABLE;
  TIM_OC_InitStruct.CompareValue = 3;
  TIM_OC_InitStruct.OCPolarity = LL_TIM_OCPOLARITY_HIGH;
  LL_TIM_OC_Init(TIM4, LL_TIM_CHANNEL_CH1, &TIM_OC_InitStruct);
  LL_TIM_OC_DisableFast(TIM4, LL_TIM_CHANNEL_CH1);
  LL_TIM_SetTriggerOutput(TIM4, LL_TIM_TRGO_UPDATE);
  LL_TIM_DisableMasterSlaveMode(TIM4);
  LL_AHB2_GRP1_EnableClock(LL_AHB2_GRP1_PERIPH_GPIOB);
  /**TIM4 GPIO Configuration
  PB6   ------> TIM4_CH1
  */
  GPIO_InitStruct.Pin = BLB6_Pin;
  GPIO_InitStruct.Mode = LL_GPIO_MODE_ALTERNATE;
  GPIO_InitStruct.Speed = LL_GPIO_SPEED_FREQ_HIGH;
  GPIO_InitStruct.OutputType = LL_GPIO_OUTPUT_PUSHPULL;
  GPIO_InitStruct.Pull = LL_GPIO_PULL_NO;
  GPIO_InitStruct.Alternate = LL_GPIO_AF_2;
  LL_GPIO_Init(BLB6_GPIO_Port, &GPIO_InitStruct);

}

static void MX_TIM5_Init(void)
{

  LL_TIM_InitTypeDef TIM_InitStruct = {0};

  LL_GPIO_InitTypeDef GPIO_InitStruct = {0};

  /* Peripheral clock enable */
  LL_APB1_GRP1_EnableClock(LL_APB1_GRP1_PERIPH_TIM5);

  LL_AHB2_GRP1_EnableClock(LL_AHB2_GRP1_PERIPH_GPIOB);
  LL_AHB2_GRP1_EnableClock(LL_AHB2_GRP1_PERIPH_GPIOC);
  /**TIM5 GPIO Configuration
  PB2   ------> TIM5_CH1
  PC12   ------> TIM5_CH2
  */
  GPIO_InitStruct.Pin = LL_GPIO_PIN_2;
  GPIO_InitStruct.Mode = LL_GPIO_MODE_ALTERNATE;
  GPIO_InitStruct.Speed = LL_GPIO_SPEED_FREQ_LOW;
  GPIO_InitStruct.OutputType = LL_GPIO_OUTPUT_PUSHPULL;
  GPIO_InitStruct.Pull = LL_GPIO_PULL_UP;
  GPIO_InitStruct.Alternate = LL_GPIO_AF_2;
  LL_GPIO_Init(GPIOB, &GPIO_InitStruct);

  GPIO_InitStruct.Pin = LL_GPIO_PIN_12;
  GPIO_InitStruct.Mode = LL_GPIO_MODE_ALTERNATE;
  GPIO_InitStruct.Speed = LL_GPIO_SPEED_FREQ_LOW;
  GPIO_InitStruct.OutputType = LL_GPIO_OUTPUT_PUSHPULL;
  GPIO_InitStruct.Pull = LL_GPIO_PULL_UP;
  GPIO_InitStruct.Alternate = LL_GPIO_AF_1;
  LL_GPIO_Init(GPIOC, &GPIO_InitStruct);

  TIM_InitStruct.Prescaler = 0;
  TIM_InitStruct.CounterMode = LL_TIM_COUNTERMODE_UP;
  TIM_InitStruct.Autoreload = 255;
  TIM_InitStruct.ClockDivision = LL_TIM_CLOCKDIVISION_DIV1;
  LL_TIM_Init(TIM5, &TIM_InitStruct);
  LL_TIM_DisableARRPreload(TIM5);
  LL_TIM_SetEncoderMode(TIM5, LL_TIM_ENCODERMODE_X4_TI12);
  LL_TIM_IC_SetActiveInput(TIM5, LL_TIM_CHANNEL_CH1, LL_TIM_ACTIVEINPUT_DIRECTTI);
  LL_TIM_IC_SetPrescaler(TIM5, LL_TIM_CHANNEL_CH1, LL_TIM_ICPSC_DIV1);
  LL_TIM_IC_SetFilter(TIM5, LL_TIM_CHANNEL_CH1, LL_TIM_IC_FILTER_FDIV4_N6);
  LL_TIM_IC_SetPolarity(TIM5, LL_TIM_CHANNEL_CH1, LL_TIM_IC_POLARITY_RISING);
  LL_TIM_IC_SetActiveInput(TIM5, LL_TIM_CHANNEL_CH2, LL_TIM_ACTIVEINPUT_DIRECTTI);
  LL_TIM_IC_SetPrescaler(TIM5, LL_TIM_CHANNEL_CH2, LL_TIM_ICPSC_DIV1);
  LL_TIM_IC_SetFilter(TIM5, LL_TIM_CHANNEL_CH2, LL_TIM_IC_FILTER_FDIV4_N6);
  LL_TIM_IC_SetPolarity(TIM5, LL_TIM_CHANNEL_CH2, LL_TIM_IC_POLARITY_RISING);
  LL_TIM_SetTriggerOutput(TIM5, LL_TIM_TRGO_RESET);
  LL_TIM_DisableMasterSlaveMode(TIM5);

}

static void MX_TIM8_Init(void)
{

  LL_TIM_InitTypeDef TIM_InitStruct = {0};

  LL_GPIO_InitTypeDef GPIO_InitStruct = {0};

  /* Peripheral clock enable */
  LL_APB2_GRP1_EnableClock(LL_APB2_GRP1_PERIPH_TIM8);

  LL_AHB2_GRP1_EnableClock(LL_AHB2_GRP1_PERIPH_GPIOC);
  /**TIM8 GPIO Configuration
  PC6   ------> TIM8_CH1
  PC7   ------> TIM8_CH2
  */
  GPIO_InitStruct.Pin = LL_GPIO_PIN_6;
  GPIO_InitStruct.Mode = LL_GPIO_MODE_ALTERNATE;
  GPIO_InitStruct.Speed = LL_GPIO_SPEED_FREQ_LOW;
  GPIO_InitStruct.OutputType = LL_GPIO_OUTPUT_PUSHPULL;
  GPIO_InitStruct.Pull = LL_GPIO_PULL_UP;
  GPIO_InitStruct.Alternate = LL_GPIO_AF_4;
  LL_GPIO_Init(GPIOC, &GPIO_InitStruct);

  GPIO_InitStruct.Pin = LL_GPIO_PIN_7;
  GPIO_InitStruct.Mode = LL_GPIO_MODE_ALTERNATE;
  GPIO_InitStruct.Speed = LL_GPIO_SPEED_FREQ_LOW;
  GPIO_InitStruct.OutputType = LL_GPIO_OUTPUT_PUSHPULL;
  GPIO_InitStruct.Pull = LL_GPIO_PULL_UP;
  GPIO_InitStruct.Alternate = LL_GPIO_AF_4;
  LL_GPIO_Init(GPIOC, &GPIO_InitStruct);

  TIM_InitStruct.Prescaler = 0;
  TIM_InitStruct.CounterMode = LL_TIM_COUNTERMODE_UP;
  TIM_InitStruct.Autoreload = 255;
  TIM_InitStruct.ClockDivision = LL_TIM_CLOCKDIVISION_DIV1;
  TIM_InitStruct.RepetitionCounter = 0;
  LL_TIM_Init(TIM8, &TIM_InitStruct);
  LL_TIM_DisableARRPreload(TIM8);
  LL_TIM_SetEncoderMode(TIM8, LL_TIM_ENCODERMODE_X4_TI12);
  LL_TIM_IC_SetActiveInput(TIM8, LL_TIM_CHANNEL_CH1, LL_TIM_ACTIVEINPUT_DIRECTTI);
  LL_TIM_IC_SetPrescaler(TIM8, LL_TIM_CHANNEL_CH1, LL_TIM_ICPSC_DIV1);
  LL_TIM_IC_SetFilter(TIM8, LL_TIM_CHANNEL_CH1, LL_TIM_IC_FILTER_FDIV4_N6);
  LL_TIM_IC_SetPolarity(TIM8, LL_TIM_CHANNEL_CH1, LL_TIM_IC_POLARITY_RISING);
  LL_TIM_IC_SetActiveInput(TIM8, LL_TIM_CHANNEL_CH2, LL_TIM_ACTIVEINPUT_DIRECTTI);
  LL_TIM_IC_SetPrescaler(TIM8, LL_TIM_CHANNEL_CH2, LL_TIM_ICPSC_DIV1);
  LL_TIM_IC_SetFilter(TIM8, LL_TIM_CHANNEL_CH2, LL_TIM_IC_FILTER_FDIV4_N6);
  LL_TIM_IC_SetPolarity(TIM8, LL_TIM_CHANNEL_CH2, LL_TIM_IC_POLARITY_RISING);
  LL_TIM_SetTriggerOutput(TIM8, LL_TIM_TRGO_RESET);
  LL_TIM_SetTriggerOutput2(TIM8, LL_TIM_TRGO2_RESET);
  LL_TIM_DisableMasterSlaveMode(TIM8);

}

static void MX_TIM15_Init(void)
{

  LL_TIM_InitTypeDef TIM_InitStruct = {0};
  LL_TIM_OC_InitTypeDef TIM_OC_InitStruct = {0};
  LL_TIM_BDTR_InitTypeDef TIM_BDTRInitStruct = {0};

  LL_GPIO_InitTypeDef GPIO_InitStruct = {0};

  /* Peripheral clock enable */
  LL_APB2_GRP1_EnableClock(LL_APB2_GRP1_PERIPH_TIM15);

  TIM_InitStruct.Prescaler = 169;
  TIM_InitStruct.CounterMode = LL_TIM_COUNTERMODE_UP;
  TIM_InitStruct.Autoreload = 99;
  TIM_InitStruct.ClockDivision = LL_TIM_CLOCKDIVISION_DIV1;
  TIM_InitStruct.RepetitionCounter = 0;
  LL_TIM_Init(TIM15, &TIM_InitStruct);
  LL_TIM_DisableARRPreload(TIM15);
  LL_TIM_SetClockSource(TIM15, LL_TIM_CLOCKSOURCE_INTERNAL);
  LL_TIM_OC_EnablePreload(TIM15, LL_TIM_CHANNEL_CH1);
  TIM_OC_InitStruct.OCMode = LL_TIM_OCMODE_PWM1;
  TIM_OC_InitStruct.OCState = LL_TIM_OCSTATE_DISABLE;
  TIM_OC_InitStruct.OCNState = LL_TIM_OCSTATE_DISABLE;
  TIM_OC_InitStruct.CompareValue = 40;
  TIM_OC_InitStruct.OCPolarity = LL_TIM_OCPOLARITY_HIGH;
  TIM_OC_InitStruct.OCNPolarity = LL_TIM_OCPOLARITY_HIGH;
  TIM_OC_InitStruct.OCIdleState = LL_TIM_OCIDLESTATE_LOW;
  TIM_OC_InitStruct.OCNIdleState = LL_TIM_OCIDLESTATE_LOW;
  LL_TIM_OC_Init(TIM15, LL_TIM_CHANNEL_CH1, &TIM_OC_InitStruct);
  LL_TIM_OC_DisableFast(TIM15, LL_TIM_CHANNEL_CH1);
  LL_TIM_OC_EnablePreload(TIM15, LL_TIM_CHANNEL_CH2);
  TIM_OC_InitStruct.CompareValue = 70;
  LL_TIM_OC_Init(TIM15, LL_TIM_CHANNEL_CH2, &TIM_OC_InitStruct);
  LL_TIM_OC_DisableFast(TIM15, LL_TIM_CHANNEL_CH2);
  LL_TIM_SetTriggerOutput(TIM15, LL_TIM_TRGO_RESET);
  LL_TIM_DisableMasterSlaveMode(TIM15);
  TIM_BDTRInitStruct.OSSRState = LL_TIM_OSSR_DISABLE;
  TIM_BDTRInitStruct.OSSIState = LL_TIM_OSSI_DISABLE;
  TIM_BDTRInitStruct.LockLevel = LL_TIM_LOCKLEVEL_OFF;
  TIM_BDTRInitStruct.DeadTime = 0;
  TIM_BDTRInitStruct.BreakState = LL_TIM_BREAK_DISABLE;
  TIM_BDTRInitStruct.BreakPolarity = LL_TIM_BREAK_POLARITY_HIGH;
  TIM_BDTRInitStruct.BreakFilter = LL_TIM_BREAK_FILTER_FDIV1;
  TIM_BDTRInitStruct.AutomaticOutput = LL_TIM_AUTOMATICOUTPUT_DISABLE;
  LL_TIM_BDTR_Init(TIM15, &TIM_BDTRInitStruct);
  LL_AHB2_GRP1_EnableClock(LL_AHB2_GRP1_PERIPH_GPIOB);
  /**TIM15 GPIO Configuration
  PB14   ------> TIM15_CH1
  PB15   ------> TIM15_CH2
  */
  GPIO_InitStruct.Pin = LL_GPIO_PIN_14;
  GPIO_InitStruct.Mode = LL_GPIO_MODE_ALTERNATE;
  GPIO_InitStruct.Speed = LL_GPIO_SPEED_FREQ_LOW;
  GPIO_InitStruct.OutputType = LL_GPIO_OUTPUT_PUSHPULL;
  GPIO_InitStruct.Pull = LL_GPIO_PULL_NO;
  GPIO_InitStruct.Alternate = LL_GPIO_AF_1;
  LL_GPIO_Init(GPIOB, &GPIO_InitStruct);

  GPIO_InitStruct.Pin = LL_GPIO_PIN_15;
  GPIO_InitStruct.Mode = LL_GPIO_MODE_ALTERNATE;
  GPIO_InitStruct.Speed = LL_GPIO_SPEED_FREQ_LOW;
  GPIO_InitStruct.OutputType = LL_GPIO_OUTPUT_PUSHPULL;
  GPIO_InitStruct.Pull = LL_GPIO_PULL_NO;
  GPIO_InitStruct.Alternate = LL_GPIO_AF_1;
  LL_GPIO_Init(GPIOB, &GPIO_InitStruct);

}

static void MX_USART2_UART_Init(void)
{

  LL_USART_InitTypeDef USART_InitStruct = {0};

  LL_GPIO_InitTypeDef GPIO_InitStruct = {0};

  LL_RCC_SetUSARTClockSource(LL_RCC_USART2_CLKSOURCE_PCLK1);

  /* Peripheral clock enable */
  LL_APB1_GRP1_EnableClock(LL_APB1_GRP1_PERIPH_USART2);

  LL_AHB2_GRP1_EnableClock(LL_AHB2_GRP1_PERIPH_GPIOA);
  /**USART2 GPIO Configuration
  PA2   ------> USART2_TX
  PA3   ------> USART2_RX
  */
  GPIO_InitStruct.Pin = LL_GPIO_PIN_2;
  GPIO_InitStruct.Mode = LL_GPIO_MODE_ALTERNATE;
  GPIO_InitStruct.Speed = LL_GPIO_SPEED_FREQ_LOW;
  GPIO_InitStruct.OutputType = LL_GPIO_OUTPUT_PUSHPULL;
  GPIO_InitStruct.Pull = LL_GPIO_PULL_NO;
  GPIO_InitStruct.Alternate = LL_GPIO_AF_7;
  LL_GPIO_Init(GPIOA, &GPIO_InitStruct);

  GPIO_InitStruct.Pin = LL_GPIO_PIN_3;
  GPIO_InitStruct.Mode = LL_GPIO_MODE_ALTERNATE;
  GPIO_InitStruct.Speed = LL_GPIO_SPEED_FREQ_LOW;
  GPIO_InitStruct.OutputType = LL_GPIO_OUTPUT_PUSHPULL;
  GPIO_InitStruct.Pull = LL_GPIO_PULL_NO;
  GPIO_InitStruct.Alternate = LL_GPIO_AF_7;
  LL_GPIO_Init(GPIOA, &GPIO_InitStruct);

  /* USART2 DMA Init */

  /* USART2_TX Init */
  LL_DMA_SetPeriphRequest(DMA1, LL_DMA_CHANNEL_1, LL_DMAMUX_REQ_USART2_TX);

  LL_DMA_SetDataTransferDirection(DMA1, LL_DMA_CHANNEL_1, LL_DMA_DIRECTION_MEMORY_TO_PERIPH);

  LL_DMA_SetChannelPriorityLevel(DMA1, LL_DMA_CHANNEL_1, LL_DMA_PRIORITY_LOW);

  LL_DMA_SetMode(DMA1, LL_DMA_CHANNEL_1, LL_DMA_MODE_NORMAL);

  LL_DMA_SetPeriphIncMode(DMA1, LL_DMA_CHANNEL_1, LL_DMA_PERIPH_NOINCREMENT);

  LL_DMA_SetMemoryIncMode(DMA1, LL_DMA_CHANNEL_1, LL_DMA_MEMORY_INCREMENT);

  LL_DMA_SetPeriphSize(DMA1, LL_DMA_CHANNEL_1, LL_DMA_PDATAALIGN_BYTE);

  LL_DMA_SetMemorySize(DMA1, LL_DMA_CHANNEL_1, LL_DMA_MDATAALIGN_BYTE);

  USART_InitStruct.PrescalerValue = LL_USART_PRESCALER_DIV1;
  USART_InitStruct.BaudRate = 115200;
  USART_InitStruct.DataWidth = LL_USART_DATAWIDTH_8B;
  USART_InitStruct.StopBits = LL_USART_STOPBITS_1;
  USART_InitStruct.Parity = LL_USART_PARITY_NONE;
  USART_InitStruct.TransferDirection = LL_USART_DIRECTION_TX_RX;
  USART_InitStruct.HardwareFlowControl = LL_USART_HWCONTROL_NONE;
  USART_InitStruct.OverSampling = LL_USART_OVERSAMPLING_16;
  LL_USART_Init(USART2, &USART_InitStruct);
  LL_USART_SetTXFIFOThreshold(USART2, LL_USART_FIFOTHRESHOLD_1_8);
  LL_USART_SetRXFIFOThreshold(USART2, LL_USART_FIFOTHRESHOLD_1_8);
  LL_USART_DisableFIFO(USART2);
  LL_USART_ConfigAsyncMode(USART2);

  LL_USART_Enable(USART2);

  /* Polling USART2 initialisation */
  while((!(LL_USART_IsActiveFlag_TEACK(USART2))) || (!(LL_USART_IsActiveFlag_REACK(USART2))))
  {
  }

}

static void MX_DMA_Init(void)
{

  /* Init with LL driver */
  /* DMA controller clock enable */
  LL_AHB1_GRP1_EnableClock(LL_AHB1_GRP1_PERIPH_DMAMUX1);
  LL_AHB1_GRP1_EnableClock(LL_AHB1_GRP1_PERIPH_DMA1);
  LL_AHB1_GRP1_EnableClock(LL_AHB1_GRP1_PERIPH_DMA2);

  /* DMA interrupt init */
  /* DMA1_Channel1_IRQn interrupt configuration */
  NVIC_SetPriority(DMA1_Channel1_IRQn, NVIC_EncodePriority(NVIC_GetPriorityGrouping(),0, 0));
  NVIC_EnableIRQ(DMA1_Channel1_IRQn);
  /* DMA1_Channel2_IRQn interrupt configuration */
  NVIC_SetPriority(DMA1_Channel2_IRQn, NVIC_EncodePriority(NVIC_GetPriorityGrouping(),0, 0));
  NVIC_EnableIRQ(DMA1_Channel2_IRQn);
  /* DMA1_Channel3_IRQn interrupt configuration */
  NVIC_SetPriority(DMA1_Channel3_IRQn, NVIC_EncodePriority(NVIC_GetPriorityGrouping(),0, 0));
  NVIC_EnableIRQ(DMA1_Channel3_IRQn);
  /* DMA2_Channel1_IRQn interrupt configuration */
  NVIC_SetPriority(DMA2_Channel1_IRQn, NVIC_EncodePriority(NVIC_GetPriorityGrouping(),0, 0));
  NVIC_EnableIRQ(DMA2_Channel1_IRQn);

}

static void MX_GPIO_Init(void)
{
  LL_GPIO_InitTypeDef GPIO_InitStruct = {0};

  /* GPIO Ports Clock Enable */
  LL_AHB2_GRP1_EnableClock(LL_AHB2_GRP1_PERIPH_GPIOE);
  LL_AHB2_GRP1_EnableClock(LL_AHB2_GRP1_PERIPH_GPIOC);
  LL_AHB2_GRP1_EnableClock(LL_AHB2_GRP1_PERIPH_GPIOF);
  LL_AHB2_GRP1_EnableClock(LL_AHB2_GRP1_PERIPH_GPIOA);
  LL_AHB2_GRP1_EnableClock(LL_AHB2_GRP1_PERIPH_GPIOB);
  LL_AHB2_GRP1_EnableClock(LL_AHB2_GRP1_PERIPH_GPIOD);

  /**/
  LL_GPIO_ResetOutputPin(BC_GPIO_Port, BC_Pin);

  /**/
  LL_GPIO_ResetOutputPin(BL_GPIO_Port, BL_Pin);

  /**/
  LL_GPIO_ResetOutputPin(LED1_GPIO_Port, LED1_Pin);

  /**/
  LL_GPIO_ResetOutputPin(B0_GPIO_Port, B0_Pin);

  /**/
  LL_GPIO_ResetOutputPin(B1_GPIO_Port, B1_Pin);

  /**/
  LL_GPIO_ResetOutputPin(B2_GPIO_Port, B2_Pin);

  /**/
  LL_GPIO_ResetOutputPin(AC_GPIO_Port, AC_Pin);

  /**/
  LL_GPIO_ResetOutputPin(AL_GPIO_Port, AL_Pin);

  /**/
  LL_GPIO_ResetOutputPin(A0_GPIO_Port, A0_Pin);

  /**/
  LL_GPIO_ResetOutputPin(A1_GPIO_Port, A1_Pin);

  /**/
  LL_GPIO_ResetOutputPin(A2_GPIO_Port, A2_Pin);

  /**/
  LL_GPIO_ResetOutputPin(PEN_GPIO_Port, PEN_Pin);

  /**/
  LL_GPIO_ResetOutputPin(LED2_GPIO_Port, LED2_Pin);

  /**/
  GPIO_InitStruct.Pin = SW3_Pin;
  GPIO_InitStruct.Mode = LL_GPIO_MODE_INPUT;
  GPIO_InitStruct.Pull = LL_GPIO_PULL_UP;
  LL_GPIO_Init(SW3_GPIO_Port, &GPIO_InitStruct);

  /**/
  GPIO_InitStruct.Pin = SW4_Pin;
  GPIO_InitStruct.Mode = LL_GPIO_MODE_INPUT;
  GPIO_InitStruct.Pull = LL_GPIO_PULL_UP;
  LL_GPIO_Init(SW4_GPIO_Port, &GPIO_InitStruct);

  /**/
  GPIO_InitStruct.Pin = ENC2_Pin;
  GPIO_InitStruct.Mode = LL_GPIO_MODE_INPUT;
  GPIO_InitStruct.Pull = LL_GPIO_PULL_UP;
  LL_GPIO_Init(ENC2_GPIO_Port, &GPIO_InitStruct);

  /**/
  GPIO_InitStruct.Pin = SW5_Pin;
  GPIO_InitStruct.Mode = LL_GPIO_MODE_INPUT;
  GPIO_InitStruct.Pull = LL_GPIO_PULL_UP;
  LL_GPIO_Init(SW5_GPIO_Port, &GPIO_InitStruct);

  /**/
  GPIO_InitStruct.Pin = BTN1_Pin;
  GPIO_InitStruct.Mode = LL_GPIO_MODE_INPUT;
  GPIO_InitStruct.Pull = LL_GPIO_PULL_UP;
  LL_GPIO_Init(BTN1_GPIO_Port, &GPIO_InitStruct);

  /**/
  GPIO_InitStruct.Pin = LL_GPIO_PIN_10;
  GPIO_InitStruct.Mode = LL_GPIO_MODE_ALTERNATE;
  GPIO_InitStruct.Speed = LL_GPIO_SPEED_FREQ_LOW;
  GPIO_InitStruct.OutputType = LL_GPIO_OUTPUT_PUSHPULL;
  GPIO_InitStruct.Pull = LL_GPIO_PULL_NO;
  GPIO_InitStruct.Alternate = LL_GPIO_AF_10;
  LL_GPIO_Init(GPIOF, &GPIO_InitStruct);

  /**/
  GPIO_InitStruct.Pin = LL_GPIO_PIN_1;
  GPIO_InitStruct.Mode = LL_GPIO_MODE_ALTERNATE;
  GPIO_InitStruct.Speed = LL_GPIO_SPEED_FREQ_LOW;
  GPIO_InitStruct.OutputType = LL_GPIO_OUTPUT_PUSHPULL;
  GPIO_InitStruct.Pull = LL_GPIO_PULL_NO;
  GPIO_InitStruct.Alternate = LL_GPIO_AF_10;
  LL_GPIO_Init(GPIOC, &GPIO_InitStruct);

  /**/
  GPIO_InitStruct.Pin = LL_GPIO_PIN_2;
  GPIO_InitStruct.Mode = LL_GPIO_MODE_ALTERNATE;
  GPIO_InitStruct.Speed = LL_GPIO_SPEED_FREQ_LOW;
  GPIO_InitStruct.OutputType = LL_GPIO_OUTPUT_PUSHPULL;
  GPIO_InitStruct.Pull = LL_GPIO_PULL_NO;
  GPIO_InitStruct.Alternate = LL_GPIO_AF_10;
  LL_GPIO_Init(GPIOC, &GPIO_InitStruct);

  /**/
  GPIO_InitStruct.Pin = LL_GPIO_PIN_3;
  GPIO_InitStruct.Mode = LL_GPIO_MODE_ALTERNATE;
  GPIO_InitStruct.Speed = LL_GPIO_SPEED_FREQ_LOW;
  GPIO_InitStruct.OutputType = LL_GPIO_OUTPUT_PUSHPULL;
  GPIO_InitStruct.Pull = LL_GPIO_PULL_NO;
  GPIO_InitStruct.Alternate = LL_GPIO_AF_10;
  LL_GPIO_Init(GPIOC, &GPIO_InitStruct);

  /**/
  GPIO_InitStruct.Pin = BC_Pin;
  GPIO_InitStruct.Mode = LL_GPIO_MODE_OUTPUT;
  GPIO_InitStruct.Speed = LL_GPIO_SPEED_FREQ_LOW;
  GPIO_InitStruct.OutputType = LL_GPIO_OUTPUT_PUSHPULL;
  GPIO_InitStruct.Pull = LL_GPIO_PULL_NO;
  LL_GPIO_Init(BC_GPIO_Port, &GPIO_InitStruct);

  /**/
  GPIO_InitStruct.Pin = BL_Pin;
  GPIO_InitStruct.Mode = LL_GPIO_MODE_OUTPUT;
  GPIO_InitStruct.Speed = LL_GPIO_SPEED_FREQ_LOW;
  GPIO_InitStruct.OutputType = LL_GPIO_OUTPUT_PUSHPULL;
  GPIO_InitStruct.Pull = LL_GPIO_PULL_NO;
  LL_GPIO_Init(BL_GPIO_Port, &GPIO_InitStruct);

  /**/
  GPIO_InitStruct.Pin = LL_GPIO_PIN_4;
  GPIO_InitStruct.Mode = LL_GPIO_MODE_ALTERNATE;
  GPIO_InitStruct.Speed = LL_GPIO_SPEED_FREQ_LOW;
  GPIO_InitStruct.OutputType = LL_GPIO_OUTPUT_PUSHPULL;
  GPIO_InitStruct.Pull = LL_GPIO_PULL_NO;
  GPIO_InitStruct.Alternate = LL_GPIO_AF_10;
  LL_GPIO_Init(GPIOC, &GPIO_InitStruct);

  /**/
  GPIO_InitStruct.Pin = LED1_Pin;
  GPIO_InitStruct.Mode = LL_GPIO_MODE_OUTPUT;
  GPIO_InitStruct.Speed = LL_GPIO_SPEED_FREQ_LOW;
  GPIO_InitStruct.OutputType = LL_GPIO_OUTPUT_PUSHPULL;
  GPIO_InitStruct.Pull = LL_GPIO_PULL_NO;
  LL_GPIO_Init(LED1_GPIO_Port, &GPIO_InitStruct);

  /**/
  GPIO_InitStruct.Pin = LL_GPIO_PIN_7;
  GPIO_InitStruct.Mode = LL_GPIO_MODE_ALTERNATE;
  GPIO_InitStruct.Speed = LL_GPIO_SPEED_FREQ_VERY_HIGH;
  GPIO_InitStruct.OutputType = LL_GPIO_OUTPUT_PUSHPULL;
  GPIO_InitStruct.Pull = LL_GPIO_PULL_NO;
  GPIO_InitStruct.Alternate = LL_GPIO_AF_12;
  LL_GPIO_Init(GPIOE, &GPIO_InitStruct);

  /**/
  GPIO_InitStruct.Pin = LL_GPIO_PIN_8;
  GPIO_InitStruct.Mode = LL_GPIO_MODE_ALTERNATE;
  GPIO_InitStruct.Speed = LL_GPIO_SPEED_FREQ_VERY_HIGH;
  GPIO_InitStruct.OutputType = LL_GPIO_OUTPUT_PUSHPULL;
  GPIO_InitStruct.Pull = LL_GPIO_PULL_NO;
  GPIO_InitStruct.Alternate = LL_GPIO_AF_12;
  LL_GPIO_Init(GPIOE, &GPIO_InitStruct);

  /**/
  GPIO_InitStruct.Pin = LL_GPIO_PIN_9;
  GPIO_InitStruct.Mode = LL_GPIO_MODE_ALTERNATE;
  GPIO_InitStruct.Speed = LL_GPIO_SPEED_FREQ_VERY_HIGH;
  GPIO_InitStruct.OutputType = LL_GPIO_OUTPUT_PUSHPULL;
  GPIO_InitStruct.Pull = LL_GPIO_PULL_NO;
  GPIO_InitStruct.Alternate = LL_GPIO_AF_12;
  LL_GPIO_Init(GPIOE, &GPIO_InitStruct);

  /**/
  GPIO_InitStruct.Pin = LL_GPIO_PIN_10;
  GPIO_InitStruct.Mode = LL_GPIO_MODE_ALTERNATE;
  GPIO_InitStruct.Speed = LL_GPIO_SPEED_FREQ_VERY_HIGH;
  GPIO_InitStruct.OutputType = LL_GPIO_OUTPUT_PUSHPULL;
  GPIO_InitStruct.Pull = LL_GPIO_PULL_NO;
  GPIO_InitStruct.Alternate = LL_GPIO_AF_12;
  LL_GPIO_Init(GPIOE, &GPIO_InitStruct);

  /**/
  GPIO_InitStruct.Pin = LL_GPIO_PIN_11;
  GPIO_InitStruct.Mode = LL_GPIO_MODE_ALTERNATE;
  GPIO_InitStruct.Speed = LL_GPIO_SPEED_FREQ_VERY_HIGH;
  GPIO_InitStruct.OutputType = LL_GPIO_OUTPUT_PUSHPULL;
  GPIO_InitStruct.Pull = LL_GPIO_PULL_NO;
  GPIO_InitStruct.Alternate = LL_GPIO_AF_12;
  LL_GPIO_Init(GPIOE, &GPIO_InitStruct);

  /**/
  GPIO_InitStruct.Pin = LL_GPIO_PIN_12;
  GPIO_InitStruct.Mode = LL_GPIO_MODE_ALTERNATE;
  GPIO_InitStruct.Speed = LL_GPIO_SPEED_FREQ_VERY_HIGH;
  GPIO_InitStruct.OutputType = LL_GPIO_OUTPUT_PUSHPULL;
  GPIO_InitStruct.Pull = LL_GPIO_PULL_NO;
  GPIO_InitStruct.Alternate = LL_GPIO_AF_12;
  LL_GPIO_Init(GPIOE, &GPIO_InitStruct);

  /**/
  GPIO_InitStruct.Pin = LL_GPIO_PIN_13;
  GPIO_InitStruct.Mode = LL_GPIO_MODE_ALTERNATE;
  GPIO_InitStruct.Speed = LL_GPIO_SPEED_FREQ_VERY_HIGH;
  GPIO_InitStruct.OutputType = LL_GPIO_OUTPUT_PUSHPULL;
  GPIO_InitStruct.Pull = LL_GPIO_PULL_NO;
  GPIO_InitStruct.Alternate = LL_GPIO_AF_12;
  LL_GPIO_Init(GPIOE, &GPIO_InitStruct);

  /**/
  GPIO_InitStruct.Pin = LL_GPIO_PIN_14;
  GPIO_InitStruct.Mode = LL_GPIO_MODE_ALTERNATE;
  GPIO_InitStruct.Speed = LL_GPIO_SPEED_FREQ_VERY_HIGH;
  GPIO_InitStruct.OutputType = LL_GPIO_OUTPUT_PUSHPULL;
  GPIO_InitStruct.Pull = LL_GPIO_PULL_NO;
  GPIO_InitStruct.Alternate = LL_GPIO_AF_12;
  LL_GPIO_Init(GPIOE, &GPIO_InitStruct);

  /**/
  GPIO_InitStruct.Pin = LL_GPIO_PIN_15;
  GPIO_InitStruct.Mode = LL_GPIO_MODE_ALTERNATE;
  GPIO_InitStruct.Speed = LL_GPIO_SPEED_FREQ_VERY_HIGH;
  GPIO_InitStruct.OutputType = LL_GPIO_OUTPUT_PUSHPULL;
  GPIO_InitStruct.Pull = LL_GPIO_PULL_NO;
  GPIO_InitStruct.Alternate = LL_GPIO_AF_12;
  LL_GPIO_Init(GPIOE, &GPIO_InitStruct);

  /**/
  GPIO_InitStruct.Pin = B0_Pin;
  GPIO_InitStruct.Mode = LL_GPIO_MODE_OUTPUT;
  GPIO_InitStruct.Speed = LL_GPIO_SPEED_FREQ_LOW;
  GPIO_InitStruct.OutputType = LL_GPIO_OUTPUT_PUSHPULL;
  GPIO_InitStruct.Pull = LL_GPIO_PULL_NO;
  LL_GPIO_Init(B0_GPIO_Port, &GPIO_InitStruct);

  /**/
  GPIO_InitStruct.Pin = B1_Pin;
  GPIO_InitStruct.Mode = LL_GPIO_MODE_OUTPUT;
  GPIO_InitStruct.Speed = LL_GPIO_SPEED_FREQ_LOW;
  GPIO_InitStruct.OutputType = LL_GPIO_OUTPUT_PUSHPULL;
  GPIO_InitStruct.Pull = LL_GPIO_PULL_NO;
  LL_GPIO_Init(B1_GPIO_Port, &GPIO_InitStruct);

  /**/
  GPIO_InitStruct.Pin = B2_Pin;
  GPIO_InitStruct.Mode = LL_GPIO_MODE_OUTPUT;
  GPIO_InitStruct.Speed = LL_GPIO_SPEED_FREQ_LOW;
  GPIO_InitStruct.OutputType = LL_GPIO_OUTPUT_PUSHPULL;
  GPIO_InitStruct.Pull = LL_GPIO_PULL_NO;
  LL_GPIO_Init(B2_GPIO_Port, &GPIO_InitStruct);

  /**/
  GPIO_InitStruct.Pin = LL_GPIO_PIN_8;
  GPIO_InitStruct.Mode = LL_GPIO_MODE_ALTERNATE;
  GPIO_InitStruct.Speed = LL_GPIO_SPEED_FREQ_VERY_HIGH;
  GPIO_InitStruct.OutputType = LL_GPIO_OUTPUT_PUSHPULL;
  GPIO_InitStruct.Pull = LL_GPIO_PULL_NO;
  GPIO_InitStruct.Alternate = LL_GPIO_AF_12;
  LL_GPIO_Init(GPIOD, &GPIO_InitStruct);

  /**/
  GPIO_InitStruct.Pin = LL_GPIO_PIN_9;
  GPIO_InitStruct.Mode = LL_GPIO_MODE_ALTERNATE;
  GPIO_InitStruct.Speed = LL_GPIO_SPEED_FREQ_VERY_HIGH;
  GPIO_InitStruct.OutputType = LL_GPIO_OUTPUT_PUSHPULL;
  GPIO_InitStruct.Pull = LL_GPIO_PULL_NO;
  GPIO_InitStruct.Alternate = LL_GPIO_AF_12;
  LL_GPIO_Init(GPIOD, &GPIO_InitStruct);

  /**/
  GPIO_InitStruct.Pin = LL_GPIO_PIN_10;
  GPIO_InitStruct.Mode = LL_GPIO_MODE_ALTERNATE;
  GPIO_InitStruct.Speed = LL_GPIO_SPEED_FREQ_VERY_HIGH;
  GPIO_InitStruct.OutputType = LL_GPIO_OUTPUT_PUSHPULL;
  GPIO_InitStruct.Pull = LL_GPIO_PULL_NO;
  GPIO_InitStruct.Alternate = LL_GPIO_AF_12;
  LL_GPIO_Init(GPIOD, &GPIO_InitStruct);

  /**/
  GPIO_InitStruct.Pin = LL_GPIO_PIN_13;
  GPIO_InitStruct.Mode = LL_GPIO_MODE_ALTERNATE;
  GPIO_InitStruct.Speed = LL_GPIO_SPEED_FREQ_VERY_HIGH;
  GPIO_InitStruct.OutputType = LL_GPIO_OUTPUT_PUSHPULL;
  GPIO_InitStruct.Pull = LL_GPIO_PULL_NO;
  GPIO_InitStruct.Alternate = LL_GPIO_AF_12;
  LL_GPIO_Init(GPIOD, &GPIO_InitStruct);

  /**/
  GPIO_InitStruct.Pin = LL_GPIO_PIN_14;
  GPIO_InitStruct.Mode = LL_GPIO_MODE_ALTERNATE;
  GPIO_InitStruct.Speed = LL_GPIO_SPEED_FREQ_VERY_HIGH;
  GPIO_InitStruct.OutputType = LL_GPIO_OUTPUT_PUSHPULL;
  GPIO_InitStruct.Pull = LL_GPIO_PULL_NO;
  GPIO_InitStruct.Alternate = LL_GPIO_AF_12;
  LL_GPIO_Init(GPIOD, &GPIO_InitStruct);

  /**/
  GPIO_InitStruct.Pin = LL_GPIO_PIN_15;
  GPIO_InitStruct.Mode = LL_GPIO_MODE_ALTERNATE;
  GPIO_InitStruct.Speed = LL_GPIO_SPEED_FREQ_VERY_HIGH;
  GPIO_InitStruct.OutputType = LL_GPIO_OUTPUT_PUSHPULL;
  GPIO_InitStruct.Pull = LL_GPIO_PULL_NO;
  GPIO_InitStruct.Alternate = LL_GPIO_AF_12;
  LL_GPIO_Init(GPIOD, &GPIO_InitStruct);

  /**/
  GPIO_InitStruct.Pin = AC_Pin;
  GPIO_InitStruct.Mode = LL_GPIO_MODE_OUTPUT;
  GPIO_InitStruct.Speed = LL_GPIO_SPEED_FREQ_LOW;
  GPIO_InitStruct.OutputType = LL_GPIO_OUTPUT_PUSHPULL;
  GPIO_InitStruct.Pull = LL_GPIO_PULL_NO;
  LL_GPIO_Init(AC_GPIO_Port, &GPIO_InitStruct);

  /**/
  GPIO_InitStruct.Pin = AL_Pin;
  GPIO_InitStruct.Mode = LL_GPIO_MODE_OUTPUT;
  GPIO_InitStruct.Speed = LL_GPIO_SPEED_FREQ_LOW;
  GPIO_InitStruct.OutputType = LL_GPIO_OUTPUT_PUSHPULL;
  GPIO_InitStruct.Pull = LL_GPIO_PULL_NO;
  LL_GPIO_Init(AL_GPIO_Port, &GPIO_InitStruct);

  /**/
  GPIO_InitStruct.Pin = A0_Pin;
  GPIO_InitStruct.Mode = LL_GPIO_MODE_OUTPUT;
  GPIO_InitStruct.Speed = LL_GPIO_SPEED_FREQ_LOW;
  GPIO_InitStruct.OutputType = LL_GPIO_OUTPUT_PUSHPULL;
  GPIO_InitStruct.Pull = LL_GPIO_PULL_NO;
  LL_GPIO_Init(A0_GPIO_Port, &GPIO_InitStruct);

  /**/
  GPIO_InitStruct.Pin = A1_Pin;
  GPIO_InitStruct.Mode = LL_GPIO_MODE_OUTPUT;
  GPIO_InitStruct.Speed = LL_GPIO_SPEED_FREQ_LOW;
  GPIO_InitStruct.OutputType = LL_GPIO_OUTPUT_PUSHPULL;
  GPIO_InitStruct.Pull = LL_GPIO_PULL_NO;
  LL_GPIO_Init(A1_GPIO_Port, &GPIO_InitStruct);

  /**/
  GPIO_InitStruct.Pin = A2_Pin;
  GPIO_InitStruct.Mode = LL_GPIO_MODE_OUTPUT;
  GPIO_InitStruct.Speed = LL_GPIO_SPEED_FREQ_LOW;
  GPIO_InitStruct.OutputType = LL_GPIO_OUTPUT_PUSHPULL;
  GPIO_InitStruct.Pull = LL_GPIO_PULL_NO;
  LL_GPIO_Init(A2_GPIO_Port, &GPIO_InitStruct);

  /**/
  GPIO_InitStruct.Pin = CHRG_Pin;
  GPIO_InitStruct.Mode = LL_GPIO_MODE_INPUT;
  GPIO_InitStruct.Pull = LL_GPIO_PULL_NO;
  LL_GPIO_Init(CHRG_GPIO_Port, &GPIO_InitStruct);

  /**/
  GPIO_InitStruct.Pin = PEN_Pin;
  GPIO_InitStruct.Mode = LL_GPIO_MODE_OUTPUT;
  GPIO_InitStruct.Speed = LL_GPIO_SPEED_FREQ_LOW;
  GPIO_InitStruct.OutputType = LL_GPIO_OUTPUT_PUSHPULL;
  GPIO_InitStruct.Pull = LL_GPIO_PULL_NO;
  LL_GPIO_Init(PEN_GPIO_Port, &GPIO_InitStruct);

  /**/
  GPIO_InitStruct.Pin = LL_GPIO_PIN_0;
  GPIO_InitStruct.Mode = LL_GPIO_MODE_ALTERNATE;
  GPIO_InitStruct.Speed = LL_GPIO_SPEED_FREQ_VERY_HIGH;
  GPIO_InitStruct.OutputType = LL_GPIO_OUTPUT_PUSHPULL;
  GPIO_InitStruct.Pull = LL_GPIO_PULL_NO;
  GPIO_InitStruct.Alternate = LL_GPIO_AF_12;
  LL_GPIO_Init(GPIOD, &GPIO_InitStruct);

  /**/
  GPIO_InitStruct.Pin = LL_GPIO_PIN_1;
  GPIO_InitStruct.Mode = LL_GPIO_MODE_ALTERNATE;
  GPIO_InitStruct.Speed = LL_GPIO_SPEED_FREQ_VERY_HIGH;
  GPIO_InitStruct.OutputType = LL_GPIO_OUTPUT_PUSHPULL;
  GPIO_InitStruct.Pull = LL_GPIO_PULL_NO;
  GPIO_InitStruct.Alternate = LL_GPIO_AF_12;
  LL_GPIO_Init(GPIOD, &GPIO_InitStruct);

  /**/
  GPIO_InitStruct.Pin = LL_GPIO_PIN_3;
  GPIO_InitStruct.Mode = LL_GPIO_MODE_ALTERNATE;
  GPIO_InitStruct.Speed = LL_GPIO_SPEED_FREQ_LOW;
  GPIO_InitStruct.OutputType = LL_GPIO_OUTPUT_PUSHPULL;
  GPIO_InitStruct.Pull = LL_GPIO_PULL_NO;
  GPIO_InitStruct.Alternate = LL_GPIO_AF_10;
  LL_GPIO_Init(GPIOD, &GPIO_InitStruct);

  /**/
  GPIO_InitStruct.Pin = LL_GPIO_PIN_4;
  GPIO_InitStruct.Mode = LL_GPIO_MODE_ALTERNATE;
  GPIO_InitStruct.Speed = LL_GPIO_SPEED_FREQ_VERY_HIGH;
  GPIO_InitStruct.OutputType = LL_GPIO_OUTPUT_PUSHPULL;
  GPIO_InitStruct.Pull = LL_GPIO_PULL_NO;
  GPIO_InitStruct.Alternate = LL_GPIO_AF_12;
  LL_GPIO_Init(GPIOD, &GPIO_InitStruct);

  /**/
  GPIO_InitStruct.Pin = LL_GPIO_PIN_5;
  GPIO_InitStruct.Mode = LL_GPIO_MODE_ALTERNATE;
  GPIO_InitStruct.Speed = LL_GPIO_SPEED_FREQ_VERY_HIGH;
  GPIO_InitStruct.OutputType = LL_GPIO_OUTPUT_PUSHPULL;
  GPIO_InitStruct.Pull = LL_GPIO_PULL_NO;
  GPIO_InitStruct.Alternate = LL_GPIO_AF_12;
  LL_GPIO_Init(GPIOD, &GPIO_InitStruct);

  /**/
  GPIO_InitStruct.Pin = LL_GPIO_PIN_7;
  GPIO_InitStruct.Mode = LL_GPIO_MODE_ALTERNATE;
  GPIO_InitStruct.Speed = LL_GPIO_SPEED_FREQ_VERY_HIGH;
  GPIO_InitStruct.OutputType = LL_GPIO_OUTPUT_PUSHPULL;
  GPIO_InitStruct.Pull = LL_GPIO_PULL_NO;
  GPIO_InitStruct.Alternate = LL_GPIO_AF_12;
  LL_GPIO_Init(GPIOD, &GPIO_InitStruct);

  /**/
  GPIO_InitStruct.Pin = LED2_Pin;
  GPIO_InitStruct.Mode = LL_GPIO_MODE_OUTPUT;
  GPIO_InitStruct.Speed = LL_GPIO_SPEED_FREQ_LOW;
  GPIO_InitStruct.OutputType = LL_GPIO_OUTPUT_PUSHPULL;
  GPIO_InitStruct.Pull = LL_GPIO_PULL_NO;
  LL_GPIO_Init(LED2_GPIO_Port, &GPIO_InitStruct);

  /**/
  GPIO_InitStruct.Pin = SW2_Pin;
  GPIO_InitStruct.Mode = LL_GPIO_MODE_INPUT;
  GPIO_InitStruct.Pull = LL_GPIO_PULL_UP;
  LL_GPIO_Init(SW2_GPIO_Port, &GPIO_InitStruct);

  /**/
  GPIO_InitStruct.Pin = ENC1_Pin;
  GPIO_InitStruct.Mode = LL_GPIO_MODE_INPUT;
  GPIO_InitStruct.Pull = LL_GPIO_PULL_UP;
  LL_GPIO_Init(ENC1_GPIO_Port, &GPIO_InitStruct);

}

void Error_Handler(void)
{
  __disable_irq();
  while (1)
  {
  }
}
